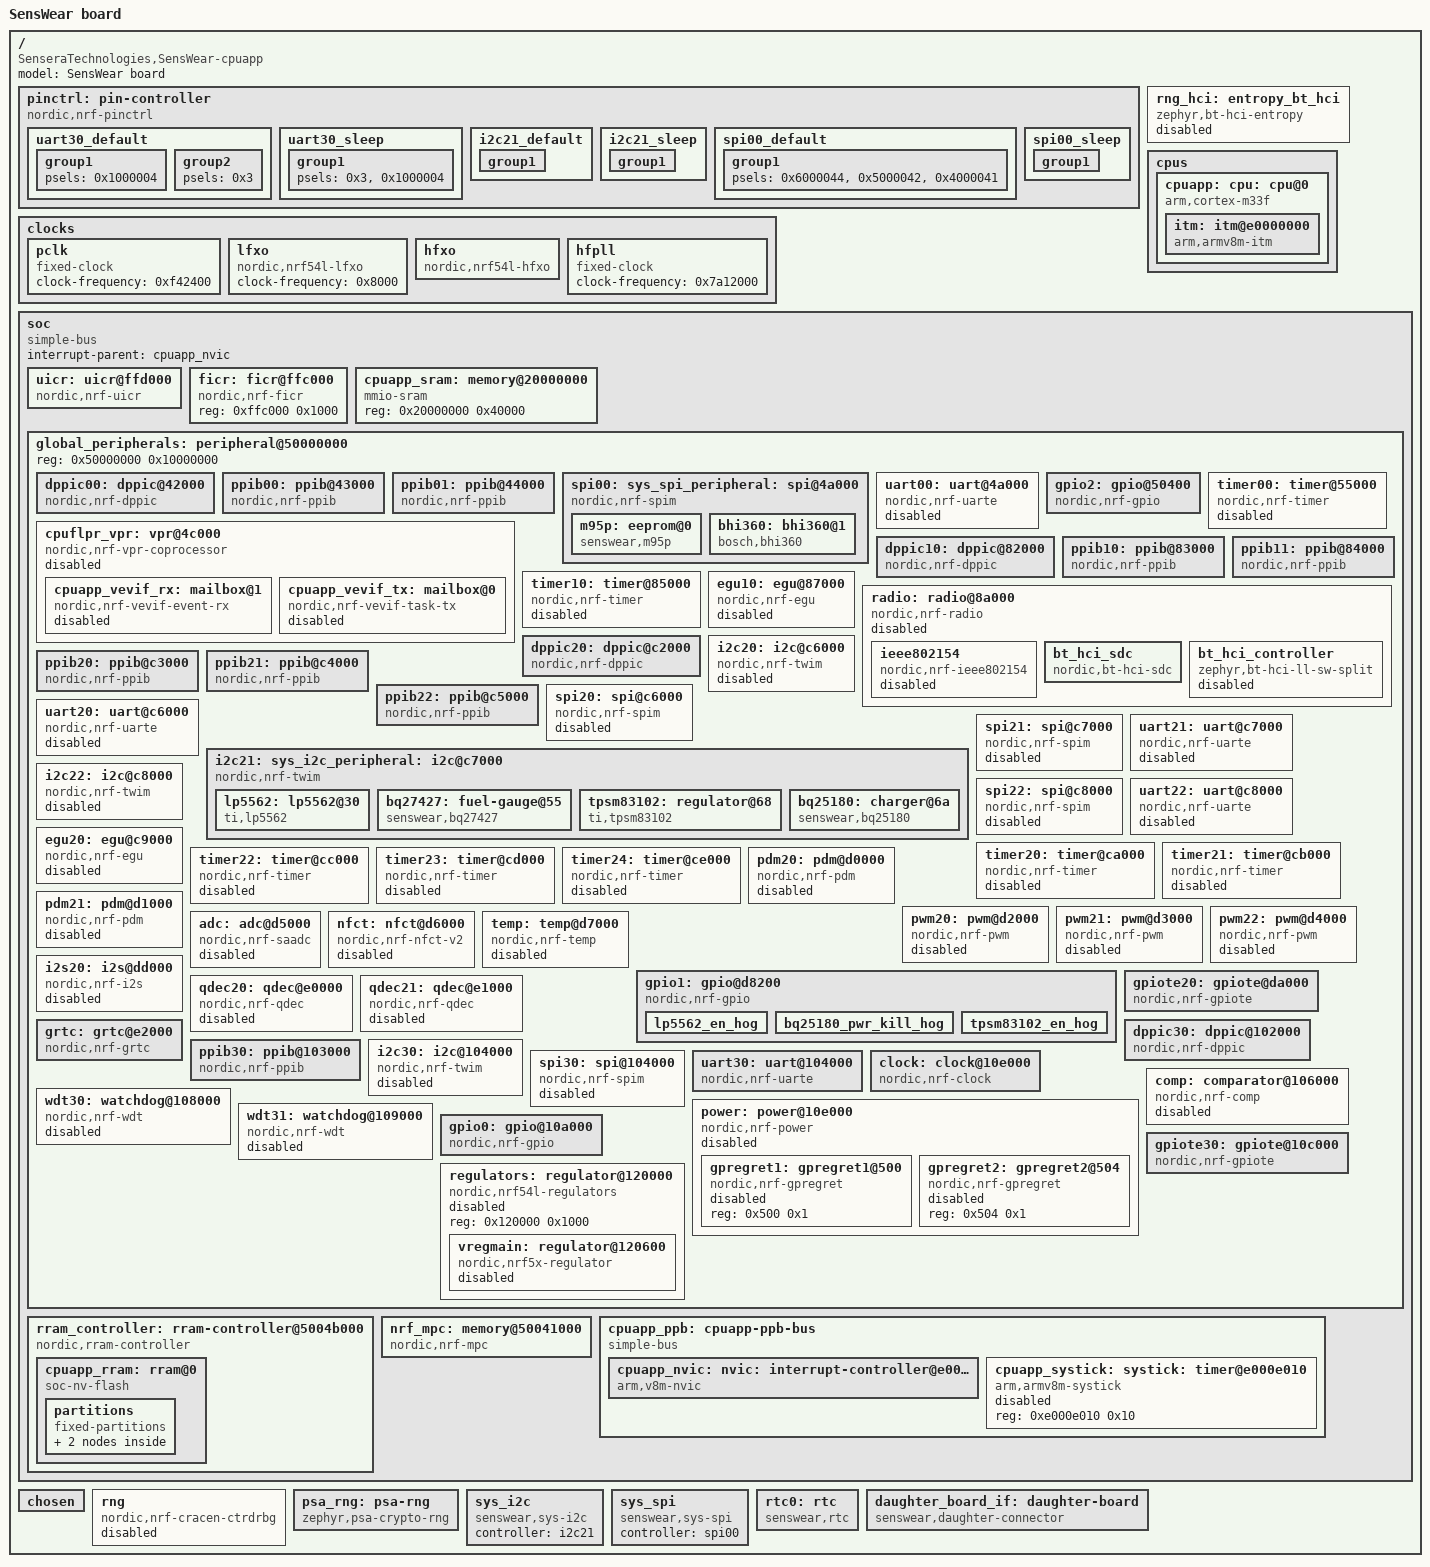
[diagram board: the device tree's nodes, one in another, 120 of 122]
/dts-v1/;

/* node '/' defined in zephyr\dts\vendor\nordic\nrf_common.dtsi:25 */
/ {
	#address-cells = < 0x1 >;                           /* in zephyr\dts\vendor\nordic\nrf54l_05_10_15.dtsi:19 */
	#size-cells = < 0x1 >;                              /* in zephyr\dts\vendor\nordic\nrf54l_05_10_15.dtsi:20 */
	model = "SensWear board";                           /* in ..\..\Users\salamid1\AppData\Local\Temp\senswear_fig4a_1164e335\boards\SenseraTechnologies\SensWear\SensWear_nrf54l15_cpuapp.dts:13 */
	compatible = "SenseraTechnologies,SensWear-cpuapp"; /* in ..\..\Users\salamid1\AppData\Local\Temp\senswear_fig4a_1164e335\boards\SenseraTechnologies\SensWear\SensWear_nrf54l15_cpuapp.dts:14 */

	/* node '/pin-controller' defined in zephyr\dts\vendor\nordic\nrf_common.dtsi:26 */
	pinctrl: pin-controller {
		compatible = "nordic,nrf-pinctrl"; /* in zephyr\dts\vendor\nordic\nrf_common.dtsi:31 */

		/* node '/pin-controller/uart30_default' defined in ..\..\Users\salamid1\AppData\Local\Temp\senswear_fig4a_1164e335\boards\SenseraTechnologies\SensWear\SensWear_nrf54l15_cpuapp.dts:121 */
		uart30_default: uart30_default {
			phandle = < 0xd >; /* in ..\..\Users\salamid1\AppData\Local\Temp\senswear_fig4a_1164e335\boards\SenseraTechnologies\SensWear\SensWear_nrf54l15_cpuapp.dts:85 */

			/* node '/pin-controller/uart30_default/group1' defined in ..\..\Users\salamid1\AppData\Local\Temp\senswear_fig4a_1164e335\boards\SenseraTechnologies\SensWear\SensWear_nrf54l15_cpuapp.dts:122 */
			group1 {
				psels = < 0x1000004 >; /* in ..\..\Users\salamid1\AppData\Local\Temp\senswear_fig4a_1164e335\boards\SenseraTechnologies\SensWear\SensWear_nrf54l15_cpuapp.dts:123 */
			};

			/* node '/pin-controller/uart30_default/group2' defined in ..\..\Users\salamid1\AppData\Local\Temp\senswear_fig4a_1164e335\boards\SenseraTechnologies\SensWear\SensWear_nrf54l15_cpuapp.dts:125 */
			group2 {
				psels = < 0x3 >; /* in ..\..\Users\salamid1\AppData\Local\Temp\senswear_fig4a_1164e335\boards\SenseraTechnologies\SensWear\SensWear_nrf54l15_cpuapp.dts:126 */
			};
		};

		/* node '/pin-controller/uart30_sleep' defined in ..\..\Users\salamid1\AppData\Local\Temp\senswear_fig4a_1164e335\boards\SenseraTechnologies\SensWear\SensWear_nrf54l15_cpuapp.dts:130 */
		uart30_sleep: uart30_sleep {
			phandle = < 0xe >; /* in ..\..\Users\salamid1\AppData\Local\Temp\senswear_fig4a_1164e335\boards\SenseraTechnologies\SensWear\SensWear_nrf54l15_cpuapp.dts:86 */

			/* node '/pin-controller/uart30_sleep/group1' defined in ..\..\Users\salamid1\AppData\Local\Temp\senswear_fig4a_1164e335\boards\SenseraTechnologies\SensWear\SensWear_nrf54l15_cpuapp.dts:131 */
			group1 {
				psels = < 0x3 >,
				        < 0x1000004 >; /* in ..\..\Users\salamid1\AppData\Local\Temp\senswear_fig4a_1164e335\boards\SenseraTechnologies\SensWear\SensWear_nrf54l15_cpuapp.dts:132 */
			};
		};

		/* node '/pin-controller/i2c21_default' defined in ..\..\Users\salamid1\AppData\Local\Temp\senswear_fig4a_1164e335\boards\SenseraTechnologies\SensWear\SensWear_nrf54l15_cpuapp.dts:137 */
		i2c21_default: i2c21_default {
			phandle = < 0x8 >; /* in ..\..\Users\salamid1\AppData\Local\Temp\senswear_fig4a_1164e335\boards\SenseraTechnologies\SensWear\SensWear_nrf54l15_cpuapp.dts:207 */

			/* node '/pin-controller/i2c21_default/group1' defined in ..\..\Users\salamid1\AppData\Local\Temp\senswear_fig4a_1164e335\boards\SenseraTechnologies\SensWear\SensWear_nrf54l15_cpuapp.dts:138 */
			group1 {
				psels = < 0xc000022 >,
				        < 0xb000023 >; /* in ..\..\Users\salamid1\AppData\Local\Temp\senswear_fig4a_1164e335\boards\SenseraTechnologies\SensWear\SensWear_nrf54l15_cpuapp.dts:139 */
				bias-pull-up;          /* in ..\..\Users\salamid1\AppData\Local\Temp\senswear_fig4a_1164e335\boards\SenseraTechnologies\SensWear\SensWear_nrf54l15_cpuapp.dts:141 */
			};
		};

		/* node '/pin-controller/i2c21_sleep' defined in ..\..\Users\salamid1\AppData\Local\Temp\senswear_fig4a_1164e335\boards\SenseraTechnologies\SensWear\SensWear_nrf54l15_cpuapp.dts:145 */
		i2c21_sleep: i2c21_sleep {
			phandle = < 0x9 >; /* in ..\..\Users\salamid1\AppData\Local\Temp\senswear_fig4a_1164e335\boards\SenseraTechnologies\SensWear\SensWear_nrf54l15_cpuapp.dts:208 */

			/* node '/pin-controller/i2c21_sleep/group1' defined in ..\..\Users\salamid1\AppData\Local\Temp\senswear_fig4a_1164e335\boards\SenseraTechnologies\SensWear\SensWear_nrf54l15_cpuapp.dts:146 */
			group1 {
				psels = < 0xc000022 >,
				        < 0xb000023 >; /* in ..\..\Users\salamid1\AppData\Local\Temp\senswear_fig4a_1164e335\boards\SenseraTechnologies\SensWear\SensWear_nrf54l15_cpuapp.dts:147 */
				low-power-enable;      /* in ..\..\Users\salamid1\AppData\Local\Temp\senswear_fig4a_1164e335\boards\SenseraTechnologies\SensWear\SensWear_nrf54l15_cpuapp.dts:149 */
			};
		};

		/* node '/pin-controller/spi00_default' defined in ..\..\Users\salamid1\AppData\Local\Temp\senswear_fig4a_1164e335\boards\SenseraTechnologies\SensWear\SensWear_nrf54l15_cpuapp.dts:153 */
		spi00_default: spi00_default {
			phandle = < 0x3 >; /* in ..\..\Users\salamid1\AppData\Local\Temp\senswear_fig4a_1164e335\boards\SenseraTechnologies\SensWear\SensWear_nrf54l15_cpuapp.dts:312 */

			/* node '/pin-controller/spi00_default/group1' defined in ..\..\Users\salamid1\AppData\Local\Temp\senswear_fig4a_1164e335\boards\SenseraTechnologies\SensWear\SensWear_nrf54l15_cpuapp.dts:154 */
			group1 {
				psels = < 0x6000044 >,
				        < 0x5000042 >,
				        < 0x4000041 >; /* in ..\..\Users\salamid1\AppData\Local\Temp\senswear_fig4a_1164e335\boards\SenseraTechnologies\SensWear\SensWear_nrf54l15_cpuapp.dts:155 */
			};
		};

		/* node '/pin-controller/spi00_sleep' defined in ..\..\Users\salamid1\AppData\Local\Temp\senswear_fig4a_1164e335\boards\SenseraTechnologies\SensWear\SensWear_nrf54l15_cpuapp.dts:161 */
		spi00_sleep: spi00_sleep {
			phandle = < 0x4 >; /* in ..\..\Users\salamid1\AppData\Local\Temp\senswear_fig4a_1164e335\boards\SenseraTechnologies\SensWear\SensWear_nrf54l15_cpuapp.dts:313 */

			/* node '/pin-controller/spi00_sleep/group1' defined in ..\..\Users\salamid1\AppData\Local\Temp\senswear_fig4a_1164e335\boards\SenseraTechnologies\SensWear\SensWear_nrf54l15_cpuapp.dts:162 */
			group1 {
				psels = < 0x6000044 >,
				        < 0x5000042 >,
				        < 0x4000041 >; /* in ..\..\Users\salamid1\AppData\Local\Temp\senswear_fig4a_1164e335\boards\SenseraTechnologies\SensWear\SensWear_nrf54l15_cpuapp.dts:163 */
				low-power-enable;      /* in ..\..\Users\salamid1\AppData\Local\Temp\senswear_fig4a_1164e335\boards\SenseraTechnologies\SensWear\SensWear_nrf54l15_cpuapp.dts:166 */
			};
		};
	};

	/* node '/entropy_bt_hci' defined in zephyr\dts\vendor\nordic\nrf_common.dtsi:34 */
	rng_hci: entropy_bt_hci {
		compatible = "zephyr,bt-hci-entropy"; /* in zephyr\dts\vendor\nordic\nrf_common.dtsi:35 */
		status = "disabled";                  /* in zephyr\dts\vendor\nordic\nrf_common.dtsi:36 */
	};

	/* node '/cpus' defined in zephyr\dts\vendor\nordic\nrf54l_05_10_15.dtsi:22 */
	cpus {
		#address-cells = < 0x1 >; /* in zephyr\dts\vendor\nordic\nrf54l_05_10_15.dtsi:23 */
		#size-cells = < 0x0 >;    /* in zephyr\dts\vendor\nordic\nrf54l_05_10_15.dtsi:24 */

		/* node '/cpus/cpu@0' defined in zephyr\dts\vendor\nordic\nrf54l_05_10_15.dtsi:26 */
		cpuapp: cpu: cpu@0 {
			compatible = "arm,cortex-m33f"; /* in zephyr\dts\vendor\nordic\nrf54l_05_10_15.dtsi:27 */
			reg = < 0x0 >;                  /* in zephyr\dts\vendor\nordic\nrf54l_05_10_15.dtsi:28 */
			device_type = "cpu";            /* in zephyr\dts\vendor\nordic\nrf54l_05_10_15.dtsi:29 */
			clocks = < &hfpll >;            /* in zephyr\dts\vendor\nordic\nrf54l_05_10_15.dtsi:30 */
			#address-cells = < 0x1 >;       /* in zephyr\dts\vendor\nordic\nrf54l_05_10_15.dtsi:31 */
			#size-cells = < 0x1 >;          /* in zephyr\dts\vendor\nordic\nrf54l_05_10_15.dtsi:32 */

			/* node '/cpus/cpu@0/itm@e0000000' defined in zephyr\dts\vendor\nordic\nrf54l_05_10_15.dtsi:34 */
			itm: itm@e0000000 {
				compatible = "arm,armv8m-itm";     /* in zephyr\dts\vendor\nordic\nrf54l_05_10_15.dtsi:35 */
				reg = < 0xe0000000 0x1000 >;       /* in zephyr\dts\vendor\nordic\nrf54l_05_10_15.dtsi:36 */
				swo-ref-frequency = < 0x7a12000 >; /* in zephyr\dts\vendor\nordic\nrf54l_05_10_15.dtsi:37 */
			};
		};
	};

	/* node '/clocks' defined in zephyr\dts\vendor\nordic\nrf54l_05_10_15.dtsi:52 */
	clocks {

		/* node '/clocks/pclk' defined in zephyr\dts\vendor\nordic\nrf54l_05_10_15.dtsi:53 */
		pclk: pclk {
			compatible = "fixed-clock";     /* in zephyr\dts\vendor\nordic\nrf54l_05_10_15.dtsi:54 */
			#clock-cells = < 0x0 >;         /* in zephyr\dts\vendor\nordic\nrf54l_05_10_15.dtsi:55 */
			clock-frequency = < 0xf42400 >; /* in zephyr\dts\vendor\nordic\nrf54l_05_10_15.dtsi:56 */
			phandle = < 0xc >;              /* in zephyr\dts\vendor\nordic\nrf54l_05_10_15.dtsi:596 */
		};

		/* node '/clocks/lfxo' defined in zephyr\dts\vendor\nordic\nrf54l_05_10_15.dtsi:59 */
		lfxo: lfxo {
			compatible = "nordic,nrf54l-lfxo"; /* in zephyr\dts\vendor\nordic\nrf54l_05_10_15.dtsi:60 */
			#clock-cells = < 0x0 >;            /* in zephyr\dts\vendor\nordic\nrf54l_05_10_15.dtsi:61 */
			clock-frequency = < 0x8000 >;      /* in zephyr\dts\vendor\nordic\nrf54l_05_10_15.dtsi:62 */
			phandle = < 0xb >;                 /* in zephyr\dts\vendor\nordic\nrf54l_05_10_15.dtsi:596 */
		};

		/* node '/clocks/hfxo' defined in zephyr\dts\vendor\nordic\nrf54l_05_10_15.dtsi:65 */
		hfxo: hfxo {
			compatible = "nordic,nrf54l-hfxo"; /* in zephyr\dts\vendor\nordic\nrf54l_05_10_15.dtsi:66 */
			#clock-cells = < 0x0 >;            /* in zephyr\dts\vendor\nordic\nrf54l_05_10_15.dtsi:67 */
			clock-frequency = < 0x1e84800 >;   /* in zephyr\dts\vendor\nordic\nrf54l_05_10_15.dtsi:68 */
			startup-time-us = < 0x672 >;       /* in zephyr\dts\vendor\nordic\nrf54l_05_10_15.dtsi:69 */
			phandle = < 0x7 >;                 /* in zephyr\dts\vendor\nordic\nrf54l_05_10_15.dtsi:243 */
		};

		/* node '/clocks/hfpll' defined in zephyr\dts\vendor\nordic\nrf54l_05_10_15.dtsi:72 */
		hfpll: hfpll {
			compatible = "fixed-clock";      /* in zephyr\dts\vendor\nordic\nrf54l_05_10_15.dtsi:73 */
			#clock-cells = < 0x0 >;          /* in zephyr\dts\vendor\nordic\nrf54l_05_10_15.dtsi:74 */
			clock-frequency = < 0x7a12000 >; /* in zephyr\dts\vendor\nordic\nrf54l_05_10_15.dtsi:75 */
			phandle = < 0x1 >;               /* in zephyr\dts\vendor\nordic\nrf54l_05_10_15.dtsi:30 */
		};
	};

	/* node '/soc' defined in zephyr\dts\vendor\nordic\nrf54l_05_10_15.dtsi:79 */
	soc {
		#address-cells = < 0x1 >;            /* in zephyr\dts\vendor\nordic\nrf54l_05_10_15.dtsi:80 */
		#size-cells = < 0x1 >;               /* in zephyr\dts\vendor\nordic\nrf54l_05_10_15.dtsi:81 */
		compatible = "simple-bus";           /* in zephyr\dts\arm\nordic\nrf54l_05_10_15_cpuapp.dtsi:23 */
		interrupt-parent = < &cpuapp_nvic >; /* in zephyr\dts\arm\nordic\nrf54l_05_10_15_cpuapp.dtsi:24 */
		ranges;                              /* in zephyr\dts\arm\nordic\nrf54l_05_10_15_cpuapp.dtsi:25 */

		/* node '/soc/uicr@ffd000' defined in zephyr\dts\vendor\nordic\nrf54l_05_10_15.dtsi:86 */
		uicr: uicr@ffd000 {
			compatible = "nordic,nrf-uicr";   /* in zephyr\dts\vendor\nordic\nrf54l_05_10_15.dtsi:87 */
			reg = < 0xffd000 0x1000 >;        /* in zephyr\dts\vendor\nordic\nrf54l_05_10_15.dtsi:88 */
			ranges = < 0x0 0xffd000 0x1000 >; /* in zephyr\dts\vendor\nordic\nrf54l_05_10_15.dtsi:89 */
			#address-cells = < 0x1 >;         /* in zephyr\dts\vendor\nordic\nrf54l_05_10_15.dtsi:90 */
			#size-cells = < 0x1 >;            /* in zephyr\dts\vendor\nordic\nrf54l_05_10_15.dtsi:91 */
			nfct-pins-as-gpios;               /* in ..\..\Users\salamid1\AppData\Local\Temp\senswear_fig4a_1164e335\boards\SenseraTechnologies\SensWear\SensWear_nrf54l15_cpuapp.dts:307 */
		};

		/* node '/soc/ficr@ffc000' defined in zephyr\dts\vendor\nordic\nrf54l_05_10_15.dtsi:95 */
		ficr: ficr@ffc000 {
			compatible = "nordic,nrf-ficr"; /* in zephyr\dts\vendor\nordic\nrf54l_05_10_15.dtsi:96 */
			reg = < 0xffc000 0x1000 >;      /* in zephyr\dts\vendor\nordic\nrf54l_05_10_15.dtsi:97 */
			#nordic,ficr-cells = < 0x1 >;   /* in zephyr\dts\vendor\nordic\nrf54l_05_10_15.dtsi:98 */
		};

		/* node '/soc/memory@20000000' defined in zephyr\dts\vendor\nordic\nrf54l_05_10_15.dtsi:101 */
		cpuapp_sram: memory@20000000 {
			compatible = "mmio-sram";            /* in zephyr\dts\vendor\nordic\nrf54l_05_10_15.dtsi:102 */
			#address-cells = < 0x1 >;            /* in zephyr\dts\vendor\nordic\nrf54l_05_10_15.dtsi:103 */
			#size-cells = < 0x1 >;               /* in zephyr\dts\vendor\nordic\nrf54l_05_10_15.dtsi:104 */
			reg = < 0x20000000 0x40000 >;        /* in zephyr\dts\vendor\nordic\nrf54l15.dtsi:10 */
			ranges = < 0x0 0x20000000 0x40000 >; /* in zephyr\dts\vendor\nordic\nrf54l15.dtsi:11 */
			status = "okay";                     /* in ..\..\Users\salamid1\AppData\Local\Temp\senswear_fig4a_1164e335\boards\SenseraTechnologies\SensWear\SensWear_nrf54l15_cpuapp.dts:100 */
		};

		/* node '/soc/peripheral@50000000' defined in zephyr\dts\vendor\nordic\nrf54l_05_10_15.dtsi:114 */
		global_peripherals: peripheral@50000000 {
			reg = < 0x50000000 0x10000000 >;        /* in zephyr\dts\vendor\nordic\nrf54l_05_10_15.dtsi:115 */
			#address-cells = < 0x1 >;               /* in zephyr\dts\vendor\nordic\nrf54l_05_10_15.dtsi:116 */
			#size-cells = < 0x1 >;                  /* in zephyr\dts\vendor\nordic\nrf54l_05_10_15.dtsi:117 */
			ranges = < 0x0 0x50000000 0x10000000 >; /* in zephyr\dts\vendor\nordic\nrf54l_05_10_15.dtsi:118 */

			/* node '/soc/peripheral@50000000/dppic@42000' defined in zephyr\dts\vendor\nordic\nrf54l_05_10_15.dtsi:121 */
			dppic00: dppic@42000 {
				compatible = "nordic,nrf-dppic"; /* in zephyr\dts\vendor\nordic\nrf54l_05_10_15.dtsi:122 */
				reg = < 0x42000 0x808 >;         /* in zephyr\dts\vendor\nordic\nrf54l_05_10_15.dtsi:123 */
				channels = < 0x8 >;              /* in zephyr\dts\vendor\nordic\nrf54l_05_10_15.dtsi:125 */
				groups = < 0x2 >;                /* in zephyr\dts\vendor\nordic\nrf54l_05_10_15.dtsi:126 */
				status = "okay";                 /* in zephyr\dts\arm\nordic\nrf54l_05_10_15_cpuapp.dtsi:95 */
			};

			/* node '/soc/peripheral@50000000/ppib@43000' defined in zephyr\dts\vendor\nordic\nrf54l_05_10_15.dtsi:129 */
			ppib00: ppib@43000 {
				compatible = "nordic,nrf-ppib"; /* in zephyr\dts\vendor\nordic\nrf54l_05_10_15.dtsi:130 */
				reg = < 0x43000 0x1000 >;       /* in zephyr\dts\vendor\nordic\nrf54l_05_10_15.dtsi:131 */
				channels = < 0x8 >;             /* in zephyr\dts\vendor\nordic\nrf54l_05_10_15.dtsi:133 */
				status = "okay";                /* in zephyr\dts\arm\nordic\nrf54l_05_10_15_cpuapp.dtsi:111 */
			};

			/* node '/soc/peripheral@50000000/ppib@44000' defined in zephyr\dts\vendor\nordic\nrf54l_05_10_15.dtsi:136 */
			ppib01: ppib@44000 {
				compatible = "nordic,nrf-ppib"; /* in zephyr\dts\vendor\nordic\nrf54l_05_10_15.dtsi:137 */
				reg = < 0x44000 0x1000 >;       /* in zephyr\dts\vendor\nordic\nrf54l_05_10_15.dtsi:138 */
				channels = < 0x8 >;             /* in zephyr\dts\vendor\nordic\nrf54l_05_10_15.dtsi:140 */
				status = "okay";                /* in zephyr\dts\arm\nordic\nrf54l_05_10_15_cpuapp.dtsi:115 */
			};

			/* node '/soc/peripheral@50000000/spi@4a000' defined in zephyr\dts\vendor\nordic\nrf54l_05_10_15.dtsi:143 */
			spi00: sys_spi_peripheral: spi@4a000 {
				compatible = "nordic,nrf-spim"; /* in zephyr\dts\vendor\nordic\nrf54l_05_10_15.dtsi:150 */
				#address-cells = < 0x1 >;       /* in zephyr\dts\vendor\nordic\nrf54l_05_10_15.dtsi:151 */
				#size-cells = < 0x0 >;          /* in zephyr\dts\vendor\nordic\nrf54l_05_10_15.dtsi:152 */
				reg = < 0x4a000 0x1000 >;       /* in zephyr\dts\vendor\nordic\nrf54l_05_10_15.dtsi:153 */
				interrupts = < 0x4a 0x1 >;      /* in zephyr\dts\vendor\nordic\nrf54l_05_10_15.dtsi:154 */
				clocks = < &hfpll >;            /* in zephyr\dts\vendor\nordic\nrf54l_05_10_15.dtsi:155 */
				max-frequency = < 0x1e84800 >;  /* in zephyr\dts\vendor\nordic\nrf54l_05_10_15.dtsi:156 */
				easydma-maxcnt-bits = < 0x10 >; /* in zephyr\dts\vendor\nordic\nrf54l_05_10_15.dtsi:157 */
				rx-delay-supported;             /* in zephyr\dts\vendor\nordic\nrf54l_05_10_15.dtsi:158 */
				rx-delay = < 0x1 >;             /* in zephyr\dts\vendor\nordic\nrf54l_05_10_15.dtsi:159 */
				status = "okay";                /* in ..\..\Users\salamid1\AppData\Local\Temp\senswear_fig4a_1164e335\boards\SenseraTechnologies\SensWear\SensWear_nrf54l15_cpuapp.dts:311 */
				pinctrl-0 = < &spi00_default >; /* in ..\..\Users\salamid1\AppData\Local\Temp\senswear_fig4a_1164e335\boards\SenseraTechnologies\SensWear\SensWear_nrf54l15_cpuapp.dts:312 */
				pinctrl-1 = < &spi00_sleep >;   /* in ..\..\Users\salamid1\AppData\Local\Temp\senswear_fig4a_1164e335\boards\SenseraTechnologies\SensWear\SensWear_nrf54l15_cpuapp.dts:313 */
				pinctrl-names = "default",
				                "sleep";        /* in ..\..\Users\salamid1\AppData\Local\Temp\senswear_fig4a_1164e335\boards\SenseraTechnologies\SensWear\SensWear_nrf54l15_cpuapp.dts:314 */
				phandle = < 0x11 >;             /* in ..\..\Users\salamid1\AppData\Local\Temp\senswear_fig4a_1164e335\boards\SenseraTechnologies\SensWear\SensWear_nrf54l15_cpuapp.dts:38 */

				/* node '/soc/peripheral@50000000/spi@4a000/eeprom@0' defined in ..\..\Users\salamid1\AppData\Local\Temp\senswear_fig4a_1164e335\boards\SenseraTechnologies\SensWear\SensWear_nrf54l15_cpuapp.dts:324 */
				m95p: eeprom@0 {
					compatible = "senswear,m95p";     /* in ..\..\Users\salamid1\AppData\Local\Temp\senswear_fig4a_1164e335\boards\SenseraTechnologies\SensWear\SensWear_nrf54l15_cpuapp.dts:325 */
					reg = < 0x0 >;                    /* in ..\..\Users\salamid1\AppData\Local\Temp\senswear_fig4a_1164e335\boards\SenseraTechnologies\SensWear\SensWear_nrf54l15_cpuapp.dts:326 */
					spi-max-frequency = < 0x7a1200 >; /* in ..\..\Users\salamid1\AppData\Local\Temp\senswear_fig4a_1164e335\boards\SenseraTechnologies\SensWear\SensWear_nrf54l15_cpuapp.dts:327 */
					cs-gpios = < &gpio2 0x3 0x1 >;    /* in ..\..\Users\salamid1\AppData\Local\Temp\senswear_fig4a_1164e335\boards\SenseraTechnologies\SensWear\SensWear_nrf54l15_cpuapp.dts:328 */
					size = < 0x400000 >;              /* in ..\..\Users\salamid1\AppData\Local\Temp\senswear_fig4a_1164e335\boards\SenseraTechnologies\SensWear\SensWear_nrf54l15_cpuapp.dts:329 */
					address-width = < 0x18 >;         /* in ..\..\Users\salamid1\AppData\Local\Temp\senswear_fig4a_1164e335\boards\SenseraTechnologies\SensWear\SensWear_nrf54l15_cpuapp.dts:330 */
					pagesize = < 0x200 >;             /* in ..\..\Users\salamid1\AppData\Local\Temp\senswear_fig4a_1164e335\boards\SenseraTechnologies\SensWear\SensWear_nrf54l15_cpuapp.dts:331 */
					timeout = < 0x64 >;               /* in ..\..\Users\salamid1\AppData\Local\Temp\senswear_fig4a_1164e335\boards\SenseraTechnologies\SensWear\SensWear_nrf54l15_cpuapp.dts:332 */
					status = "okay";                  /* in ..\..\Users\salamid1\AppData\Local\Temp\senswear_fig4a_1164e335\boards\SenseraTechnologies\SensWear\SensWear_nrf54l15_cpuapp.dts:333 */
				};

				/* node '/soc/peripheral@50000000/spi@4a000/bhi360@1' defined in ..\..\Users\salamid1\AppData\Local\Temp\senswear_fig4a_1164e335\boards\SenseraTechnologies\SensWear\SensWear_nrf54l15_cpuapp.dts:339 */
				bhi360: bhi360@1 {
					compatible = "bosch,bhi360";      /* in ..\..\Users\salamid1\AppData\Local\Temp\senswear_fig4a_1164e335\boards\SenseraTechnologies\SensWear\SensWear_nrf54l15_cpuapp.dts:340 */
					reg = < 0x1 >;                    /* in ..\..\Users\salamid1\AppData\Local\Temp\senswear_fig4a_1164e335\boards\SenseraTechnologies\SensWear\SensWear_nrf54l15_cpuapp.dts:341 */
					spi-max-frequency = < 0x7a1200 >; /* in ..\..\Users\salamid1\AppData\Local\Temp\senswear_fig4a_1164e335\boards\SenseraTechnologies\SensWear\SensWear_nrf54l15_cpuapp.dts:342 */
					cs-gpios = < &gpio2 0x5 0x1 >;    /* in ..\..\Users\salamid1\AppData\Local\Temp\senswear_fig4a_1164e335\boards\SenseraTechnologies\SensWear\SensWear_nrf54l15_cpuapp.dts:343 */
					int-gpios = < &gpio1 0x9 0x1 >;   /* in ..\..\Users\salamid1\AppData\Local\Temp\senswear_fig4a_1164e335\boards\SenseraTechnologies\SensWear\SensWear_nrf54l15_cpuapp.dts:344 */
					reset-gpios = < &gpio2 0x7 0x1 >; /* in ..\..\Users\salamid1\AppData\Local\Temp\senswear_fig4a_1164e335\boards\SenseraTechnologies\SensWear\SensWear_nrf54l15_cpuapp.dts:345 */
					gpio0-gpios = < &gpio1 0xa 0x0 >; /* in ..\..\Users\salamid1\AppData\Local\Temp\senswear_fig4a_1164e335\boards\SenseraTechnologies\SensWear\SensWear_nrf54l15_cpuapp.dts:346 */
					gpio1-gpios = < &gpio2 0x6 0x0 >; /* in ..\..\Users\salamid1\AppData\Local\Temp\senswear_fig4a_1164e335\boards\SenseraTechnologies\SensWear\SensWear_nrf54l15_cpuapp.dts:347 */
					status = "okay";                  /* in ..\..\Users\salamid1\AppData\Local\Temp\senswear_fig4a_1164e335\boards\SenseraTechnologies\SensWear\SensWear_nrf54l15_cpuapp.dts:348 */
				};
			};

			/* node '/soc/peripheral@50000000/uart@4a000' defined in zephyr\dts\vendor\nordic\nrf54l_05_10_15.dtsi:163 */
			uart00: uart@4a000 {
				compatible = "nordic,nrf-uarte"; /* in zephyr\dts\vendor\nordic\nrf54l_05_10_15.dtsi:164 */
				reg = < 0x4a000 0x1000 >;        /* in zephyr\dts\vendor\nordic\nrf54l_05_10_15.dtsi:165 */
				interrupts = < 0x4a 0x1 >;       /* in zephyr\dts\vendor\nordic\nrf54l_05_10_15.dtsi:166 */
				clocks = < &hfpll >;             /* in zephyr\dts\vendor\nordic\nrf54l_05_10_15.dtsi:167 */
				status = "disabled";             /* in zephyr\dts\vendor\nordic\nrf54l_05_10_15.dtsi:168 */
				endtx-stoptx-supported;          /* in zephyr\dts\vendor\nordic\nrf54l_05_10_15.dtsi:169 */
				frame-timeout-supported;         /* in zephyr\dts\vendor\nordic\nrf54l_05_10_15.dtsi:170 */
			};

			/* node '/soc/peripheral@50000000/vpr@4c000' defined in zephyr\dts\vendor\nordic\nrf54l_05_10_15.dtsi:173 */
			cpuflpr_vpr: vpr@4c000 {
				compatible = "nordic,nrf-vpr-coprocessor"; /* in zephyr\dts\vendor\nordic\nrf54l_05_10_15.dtsi:174 */
				reg = < 0x4c000 0x1000 >;                  /* in zephyr\dts\vendor\nordic\nrf54l_05_10_15.dtsi:175 */
				ranges = < 0x0 0x4c000 0x1000 >;           /* in zephyr\dts\vendor\nordic\nrf54l_05_10_15.dtsi:176 */
				#address-cells = < 0x1 >;                  /* in zephyr\dts\vendor\nordic\nrf54l_05_10_15.dtsi:177 */
				#size-cells = < 0x1 >;                     /* in zephyr\dts\vendor\nordic\nrf54l_05_10_15.dtsi:178 */
				status = "disabled";                       /* in zephyr\dts\vendor\nordic\nrf54l_05_10_15.dtsi:179 */
				enable-secure;                             /* in zephyr\dts\vendor\nordic\nrf54l_05_10_15.dtsi:180 */
				hibernation-ram-block = < 0x20 >;          /* in zephyr\dts\vendor\nordic\nrf54l_05_10_15.dtsi:181 */

				/* node '/soc/peripheral@50000000/vpr@4c000/mailbox@1' defined in zephyr\dts\arm\nordic\nrf54l_05_10_15_cpuapp.dtsi:44 */
				cpuapp_vevif_rx: mailbox@1 {
					compatible = "nordic,nrf-vevif-event-rx"; /* in zephyr\dts\arm\nordic\nrf54l_05_10_15_cpuapp.dtsi:45 */
					reg = < 0x1 0x1000 >;                     /* in zephyr\dts\arm\nordic\nrf54l_05_10_15_cpuapp.dtsi:46 */
					status = "disabled";                      /* in zephyr\dts\arm\nordic\nrf54l_05_10_15_cpuapp.dtsi:47 */
					interrupts = < 0x4c 0x1 >;                /* in zephyr\dts\arm\nordic\nrf54l_05_10_15_cpuapp.dtsi:48 */
					#mbox-cells = < 0x1 >;                    /* in zephyr\dts\arm\nordic\nrf54l_05_10_15_cpuapp.dtsi:49 */
					nordic,events = < 0x1 >;                  /* in zephyr\dts\arm\nordic\nrf54l_05_10_15_cpuapp.dtsi:50 */
					nordic,events-mask = < 0x100000 >;        /* in zephyr\dts\arm\nordic\nrf54l_05_10_15_cpuapp.dtsi:51 */
				};

				/* node '/soc/peripheral@50000000/vpr@4c000/mailbox@0' defined in zephyr\dts\arm\nordic\nrf54l_05_10_15_cpuapp.dtsi:54 */
				cpuapp_vevif_tx: mailbox@0 {
					compatible = "nordic,nrf-vevif-task-tx"; /* in zephyr\dts\arm\nordic\nrf54l_05_10_15_cpuapp.dtsi:55 */
					reg = < 0x0 0x1000 >;                    /* in zephyr\dts\arm\nordic\nrf54l_05_10_15_cpuapp.dtsi:56 */
					#mbox-cells = < 0x1 >;                   /* in zephyr\dts\arm\nordic\nrf54l_05_10_15_cpuapp.dtsi:57 */
					nordic,tasks = < 0x7 >;                  /* in zephyr\dts\arm\nordic\nrf54l_05_10_15_cpuapp.dtsi:58 */
					nordic,tasks-mask = < 0x7f0000 >;        /* in zephyr\dts\arm\nordic\nrf54l_05_10_15_cpuapp.dtsi:59 */
					status = "disabled";                     /* in zephyr\dts\arm\nordic\nrf54l_05_10_15_cpuapp.dtsi:60 */
				};
			};

			/* node '/soc/peripheral@50000000/gpio@50400' defined in zephyr\dts\vendor\nordic\nrf54l_05_10_15.dtsi:193 */
			gpio2: gpio@50400 {
				compatible = "nordic,nrf-gpio"; /* in zephyr\dts\vendor\nordic\nrf54l_05_10_15.dtsi:194 */
				gpio-controller;                /* in zephyr\dts\vendor\nordic\nrf54l_05_10_15.dtsi:195 */
				reg = < 0x50400 0x300 >;        /* in zephyr\dts\vendor\nordic\nrf54l_05_10_15.dtsi:196 */
				#gpio-cells = < 0x2 >;          /* in zephyr\dts\vendor\nordic\nrf54l_05_10_15.dtsi:197 */
				ngpios = < 0xb >;               /* in zephyr\dts\vendor\nordic\nrf54l_05_10_15.dtsi:198 */
				port = < 0x2 >;                 /* in zephyr\dts\vendor\nordic\nrf54l_05_10_15.dtsi:200 */
				status = "okay";                /* in ..\..\Users\salamid1\AppData\Local\Temp\senswear_fig4a_1164e335\boards\SenseraTechnologies\SensWear\SensWear_nrf54l15_cpuapp.dts:303 */
				phandle = < 0x5 >;              /* in ..\..\Users\salamid1\AppData\Local\Temp\senswear_fig4a_1164e335\boards\SenseraTechnologies\SensWear\SensWear_nrf54l15_cpuapp.dts:328 */
			};

			/* node '/soc/peripheral@50000000/timer@55000' defined in zephyr\dts\vendor\nordic\nrf54l_05_10_15.dtsi:203 */
			timer00: timer@55000 {
				compatible = "nordic,nrf-timer"; /* in zephyr\dts\vendor\nordic\nrf54l_05_10_15.dtsi:204 */
				status = "disabled";             /* in zephyr\dts\vendor\nordic\nrf54l_05_10_15.dtsi:205 */
				reg = < 0x55000 0x1000 >;        /* in zephyr\dts\vendor\nordic\nrf54l_05_10_15.dtsi:206 */
				cc-num = < 0x6 >;                /* in zephyr\dts\vendor\nordic\nrf54l_05_10_15.dtsi:207 */
				max-bit-width = < 0x20 >;        /* in zephyr\dts\vendor\nordic\nrf54l_05_10_15.dtsi:208 */
				interrupts = < 0x55 0x1 >;       /* in zephyr\dts\vendor\nordic\nrf54l_05_10_15.dtsi:209 */
				clocks = < &hfpll >;             /* in zephyr\dts\vendor\nordic\nrf54l_05_10_15.dtsi:210 */
				prescaler = < 0x0 >;             /* in zephyr\dts\vendor\nordic\nrf54l_05_10_15.dtsi:211 */
			};

			/* node '/soc/peripheral@50000000/dppic@82000' defined in zephyr\dts\vendor\nordic\nrf54l_05_10_15.dtsi:214 */
			dppic10: dppic@82000 {
				compatible = "nordic,nrf-dppic"; /* in zephyr\dts\vendor\nordic\nrf54l_05_10_15.dtsi:215 */
				reg = < 0x82000 0x808 >;         /* in zephyr\dts\vendor\nordic\nrf54l_05_10_15.dtsi:216 */
				channels = < 0x18 >;             /* in zephyr\dts\vendor\nordic\nrf54l_05_10_15.dtsi:218 */
				groups = < 0x6 >;                /* in zephyr\dts\vendor\nordic\nrf54l_05_10_15.dtsi:219 */
				status = "okay";                 /* in zephyr\dts\arm\nordic\nrf54l_05_10_15_cpuapp.dtsi:99 */
			};

			/* node '/soc/peripheral@50000000/ppib@83000' defined in zephyr\dts\vendor\nordic\nrf54l_05_10_15.dtsi:222 */
			ppib10: ppib@83000 {
				compatible = "nordic,nrf-ppib"; /* in zephyr\dts\vendor\nordic\nrf54l_05_10_15.dtsi:223 */
				reg = < 0x83000 0x1000 >;       /* in zephyr\dts\vendor\nordic\nrf54l_05_10_15.dtsi:224 */
				channels = < 0x8 >;             /* in zephyr\dts\vendor\nordic\nrf54l_05_10_15.dtsi:226 */
				status = "okay";                /* in zephyr\dts\arm\nordic\nrf54l_05_10_15_cpuapp.dtsi:119 */
			};

			/* node '/soc/peripheral@50000000/ppib@84000' defined in zephyr\dts\vendor\nordic\nrf54l_05_10_15.dtsi:229 */
			ppib11: ppib@84000 {
				compatible = "nordic,nrf-ppib"; /* in zephyr\dts\vendor\nordic\nrf54l_05_10_15.dtsi:230 */
				reg = < 0x84000 0x1000 >;       /* in zephyr\dts\vendor\nordic\nrf54l_05_10_15.dtsi:231 */
				channels = < 0x10 >;            /* in zephyr\dts\vendor\nordic\nrf54l_05_10_15.dtsi:233 */
				status = "okay";                /* in zephyr\dts\arm\nordic\nrf54l_05_10_15_cpuapp.dtsi:123 */
			};

			/* node '/soc/peripheral@50000000/timer@85000' defined in zephyr\dts\vendor\nordic\nrf54l_05_10_15.dtsi:236 */
			timer10: timer@85000 {
				compatible = "nordic,nrf-timer"; /* in zephyr\dts\vendor\nordic\nrf54l_05_10_15.dtsi:237 */
				status = "disabled";             /* in zephyr\dts\vendor\nordic\nrf54l_05_10_15.dtsi:238 */
				reg = < 0x85000 0x1000 >;        /* in zephyr\dts\vendor\nordic\nrf54l_05_10_15.dtsi:239 */
				cc-num = < 0x8 >;                /* in zephyr\dts\vendor\nordic\nrf54l_05_10_15.dtsi:240 */
				max-bit-width = < 0x20 >;        /* in zephyr\dts\vendor\nordic\nrf54l_05_10_15.dtsi:241 */
				interrupts = < 0x85 0x1 >;       /* in zephyr\dts\vendor\nordic\nrf54l_05_10_15.dtsi:242 */
				clocks = < &hfxo >;              /* in zephyr\dts\vendor\nordic\nrf54l_05_10_15.dtsi:243 */
				prescaler = < 0x0 >;             /* in zephyr\dts\vendor\nordic\nrf54l_05_10_15.dtsi:244 */
			};

			/* node '/soc/peripheral@50000000/egu@87000' defined in zephyr\dts\vendor\nordic\nrf54l_05_10_15.dtsi:247 */
			egu10: egu@87000 {
				compatible = "nordic,nrf-egu"; /* in zephyr\dts\vendor\nordic\nrf54l_05_10_15.dtsi:248 */
				reg = < 0x87000 0x1000 >;      /* in zephyr\dts\vendor\nordic\nrf54l_05_10_15.dtsi:249 */
				interrupts = < 0x87 0x1 >;     /* in zephyr\dts\vendor\nordic\nrf54l_05_10_15.dtsi:250 */
				status = "disabled";           /* in zephyr\dts\vendor\nordic\nrf54l_05_10_15.dtsi:251 */
			};

			/* node '/soc/peripheral@50000000/radio@8a000' defined in zephyr\dts\vendor\nordic\nrf54l_05_10_15.dtsi:254 */
			radio: radio@8a000 {
				compatible = "nordic,nrf-radio"; /* in zephyr\dts\vendor\nordic\nrf54l_05_10_15.dtsi:255 */
				reg = < 0x8a000 0x1000 >;        /* in zephyr\dts\vendor\nordic\nrf54l_05_10_15.dtsi:256 */
				interrupts = < 0x8a 0x1 >;       /* in zephyr\dts\vendor\nordic\nrf54l_05_10_15.dtsi:257 */
				status = "disabled";             /* in zephyr\dts\vendor\nordic\nrf54l_05_10_15.dtsi:258 */
				dfe-supported;                   /* in zephyr\dts\vendor\nordic\nrf54l_05_10_15.dtsi:259 */
				ieee802154-supported;            /* in zephyr\dts\vendor\nordic\nrf54l_05_10_15.dtsi:260 */
				ble-2mbps-supported;             /* in zephyr\dts\vendor\nordic\nrf54l_05_10_15.dtsi:261 */
				ble-coded-phy-supported;         /* in zephyr\dts\vendor\nordic\nrf54l_05_10_15.dtsi:262 */
				ble-cs-supported;                /* in zephyr\dts\vendor\nordic\nrf54l_05_10_15.dtsi:263 */

				/* node '/soc/peripheral@50000000/radio@8a000/ieee802154' defined in zephyr\dts\vendor\nordic\nrf54l_05_10_15.dtsi:265 */
				ieee802154: ieee802154 {
					compatible = "nordic,nrf-ieee802154"; /* in zephyr\dts\vendor\nordic\nrf54l_05_10_15.dtsi:266 */
					status = "disabled";                  /* in zephyr\dts\vendor\nordic\nrf54l_05_10_15.dtsi:267 */
				};

				/* node '/soc/peripheral@50000000/radio@8a000/bt_hci_sdc' defined in zephyr\dts\vendor\nordic\nrf54l_05_10_15.dtsi:270 */
				bt_hci_sdc: bt_hci_sdc {
					compatible = "nordic,bt-hci-sdc"; /* in zephyr\dts\vendor\nordic\nrf54l_05_10_15.dtsi:271 */
					status = "okay";                  /* in zephyr\dts\arm\nordic\nrf54l_05_10_15_cpuapp.dtsi:40 */
				};

				/* node '/soc/peripheral@50000000/radio@8a000/bt_hci_controller' defined in zephyr\dts\vendor\nordic\nrf54l_05_10_15.dtsi:275 */
				bt_hci_controller: bt_hci_controller {
					compatible = "zephyr,bt-hci-ll-sw-split"; /* in zephyr\dts\vendor\nordic\nrf54l_05_10_15.dtsi:276 */
					status = "disabled";                      /* in zephyr\dts\vendor\nordic\nrf54l_05_10_15.dtsi:277 */
				};
			};

			/* node '/soc/peripheral@50000000/dppic@c2000' defined in zephyr\dts\vendor\nordic\nrf54l_05_10_15.dtsi:281 */
			dppic20: dppic@c2000 {
				compatible = "nordic,nrf-dppic"; /* in zephyr\dts\vendor\nordic\nrf54l_05_10_15.dtsi:282 */
				reg = < 0xc2000 0x808 >;         /* in zephyr\dts\vendor\nordic\nrf54l_05_10_15.dtsi:283 */
				channels = < 0x10 >;             /* in zephyr\dts\vendor\nordic\nrf54l_05_10_15.dtsi:285 */
				groups = < 0x6 >;                /* in zephyr\dts\vendor\nordic\nrf54l_05_10_15.dtsi:286 */
				status = "okay";                 /* in zephyr\dts\arm\nordic\nrf54l_05_10_15_cpuapp.dtsi:103 */
			};

			/* node '/soc/peripheral@50000000/ppib@c3000' defined in zephyr\dts\vendor\nordic\nrf54l_05_10_15.dtsi:289 */
			ppib20: ppib@c3000 {
				compatible = "nordic,nrf-ppib"; /* in zephyr\dts\vendor\nordic\nrf54l_05_10_15.dtsi:290 */
				reg = < 0xc3000 0x1000 >;       /* in zephyr\dts\vendor\nordic\nrf54l_05_10_15.dtsi:291 */
				channels = < 0x8 >;             /* in zephyr\dts\vendor\nordic\nrf54l_05_10_15.dtsi:293 */
				status = "okay";                /* in zephyr\dts\arm\nordic\nrf54l_05_10_15_cpuapp.dtsi:127 */
			};

			/* node '/soc/peripheral@50000000/ppib@c4000' defined in zephyr\dts\vendor\nordic\nrf54l_05_10_15.dtsi:296 */
			ppib21: ppib@c4000 {
				compatible = "nordic,nrf-ppib"; /* in zephyr\dts\vendor\nordic\nrf54l_05_10_15.dtsi:297 */
				reg = < 0xc4000 0x1000 >;       /* in zephyr\dts\vendor\nordic\nrf54l_05_10_15.dtsi:298 */
				channels = < 0x10 >;            /* in zephyr\dts\vendor\nordic\nrf54l_05_10_15.dtsi:300 */
				status = "okay";                /* in zephyr\dts\arm\nordic\nrf54l_05_10_15_cpuapp.dtsi:131 */
			};

			/* node '/soc/peripheral@50000000/ppib@c5000' defined in zephyr\dts\vendor\nordic\nrf54l_05_10_15.dtsi:303 */
			ppib22: ppib@c5000 {
				compatible = "nordic,nrf-ppib"; /* in zephyr\dts\vendor\nordic\nrf54l_05_10_15.dtsi:304 */
				reg = < 0xc5000 0x1000 >;       /* in zephyr\dts\vendor\nordic\nrf54l_05_10_15.dtsi:305 */
				channels = < 0x4 >;             /* in zephyr\dts\vendor\nordic\nrf54l_05_10_15.dtsi:307 */
				status = "okay";                /* in zephyr\dts\arm\nordic\nrf54l_05_10_15_cpuapp.dtsi:135 */
			};

			/* node '/soc/peripheral@50000000/i2c@c6000' defined in zephyr\dts\vendor\nordic\nrf54l_05_10_15.dtsi:310 */
			i2c20: i2c@c6000 {
				compatible = "nordic,nrf-twim";    /* in zephyr\dts\vendor\nordic\nrf54l_05_10_15.dtsi:311 */
				#address-cells = < 0x1 >;          /* in zephyr\dts\vendor\nordic\nrf54l_05_10_15.dtsi:312 */
				#size-cells = < 0x0 >;             /* in zephyr\dts\vendor\nordic\nrf54l_05_10_15.dtsi:313 */
				reg = < 0xc6000 0x1000 >;          /* in zephyr\dts\vendor\nordic\nrf54l_05_10_15.dtsi:314 */
				interrupts = < 0xc6 0x1 >;         /* in zephyr\dts\vendor\nordic\nrf54l_05_10_15.dtsi:315 */
				easydma-maxcnt-bits = < 0x10 >;    /* in zephyr\dts\vendor\nordic\nrf54l_05_10_15.dtsi:316 */
				clock-tolerance-percent = < 0x6 >; /* in zephyr\dts\vendor\nordic\nrf54l_05_10_15.dtsi:317 */
				status = "disabled";               /* in zephyr\dts\vendor\nordic\nrf54l_05_10_15.dtsi:318 */
				zephyr,pm-device-runtime-auto;     /* in zephyr\dts\vendor\nordic\nrf54l_05_10_15.dtsi:319 */
			};

			/* node '/soc/peripheral@50000000/spi@c6000' defined in zephyr\dts\vendor\nordic\nrf54l_05_10_15.dtsi:322 */
			spi20: spi@c6000 {
				compatible = "nordic,nrf-spim"; /* in zephyr\dts\vendor\nordic\nrf54l_05_10_15.dtsi:329 */
				#address-cells = < 0x1 >;       /* in zephyr\dts\vendor\nordic\nrf54l_05_10_15.dtsi:330 */
				#size-cells = < 0x0 >;          /* in zephyr\dts\vendor\nordic\nrf54l_05_10_15.dtsi:331 */
				reg = < 0xc6000 0x1000 >;       /* in zephyr\dts\vendor\nordic\nrf54l_05_10_15.dtsi:332 */
				interrupts = < 0xc6 0x1 >;      /* in zephyr\dts\vendor\nordic\nrf54l_05_10_15.dtsi:333 */
				max-frequency = < 0x7a1200 >;   /* in zephyr\dts\vendor\nordic\nrf54l_05_10_15.dtsi:334 */
				easydma-maxcnt-bits = < 0x10 >; /* in zephyr\dts\vendor\nordic\nrf54l_05_10_15.dtsi:335 */
				rx-delay-supported;             /* in zephyr\dts\vendor\nordic\nrf54l_05_10_15.dtsi:336 */
				rx-delay = < 0x1 >;             /* in zephyr\dts\vendor\nordic\nrf54l_05_10_15.dtsi:337 */
				status = "disabled";            /* in zephyr\dts\vendor\nordic\nrf54l_05_10_15.dtsi:338 */
			};

			/* node '/soc/peripheral@50000000/uart@c6000' defined in zephyr\dts\vendor\nordic\nrf54l_05_10_15.dtsi:341 */
			uart20: uart@c6000 {
				compatible = "nordic,nrf-uarte"; /* in zephyr\dts\vendor\nordic\nrf54l_05_10_15.dtsi:342 */
				reg = < 0xc6000 0x1000 >;        /* in zephyr\dts\vendor\nordic\nrf54l_05_10_15.dtsi:343 */
				interrupts = < 0xc6 0x1 >;       /* in zephyr\dts\vendor\nordic\nrf54l_05_10_15.dtsi:344 */
				status = "disabled";             /* in zephyr\dts\vendor\nordic\nrf54l_05_10_15.dtsi:345 */
				endtx-stoptx-supported;          /* in zephyr\dts\vendor\nordic\nrf54l_05_10_15.dtsi:346 */
				frame-timeout-supported;         /* in zephyr\dts\vendor\nordic\nrf54l_05_10_15.dtsi:347 */
			};

			/* node '/soc/peripheral@50000000/i2c@c7000' defined in zephyr\dts\vendor\nordic\nrf54l_05_10_15.dtsi:350 */
			i2c21: sys_i2c_peripheral: i2c@c7000 {
				#address-cells = < 0x1 >;          /* in zephyr\dts\vendor\nordic\nrf54l_05_10_15.dtsi:352 */
				#size-cells = < 0x0 >;             /* in zephyr\dts\vendor\nordic\nrf54l_05_10_15.dtsi:353 */
				reg = < 0xc7000 0x1000 >;          /* in zephyr\dts\vendor\nordic\nrf54l_05_10_15.dtsi:354 */
				interrupts = < 0xc7 0x1 >;         /* in zephyr\dts\vendor\nordic\nrf54l_05_10_15.dtsi:355 */
				easydma-maxcnt-bits = < 0x10 >;    /* in zephyr\dts\vendor\nordic\nrf54l_05_10_15.dtsi:356 */
				clock-tolerance-percent = < 0x6 >; /* in zephyr\dts\vendor\nordic\nrf54l_05_10_15.dtsi:357 */
				zephyr,pm-device-runtime-auto;     /* in zephyr\dts\vendor\nordic\nrf54l_05_10_15.dtsi:359 */
				status = "okay";                   /* in ..\..\Users\salamid1\AppData\Local\Temp\senswear_fig4a_1164e335\boards\SenseraTechnologies\SensWear\SensWear_nrf54l15_cpuapp.dts:204 */
				compatible = "nordic,nrf-twim";    /* in ..\..\Users\salamid1\AppData\Local\Temp\senswear_fig4a_1164e335\boards\SenseraTechnologies\SensWear\SensWear_nrf54l15_cpuapp.dts:205 */
				clock-frequency = < 0x186a0 >;     /* in ..\..\Users\salamid1\AppData\Local\Temp\senswear_fig4a_1164e335\boards\SenseraTechnologies\SensWear\SensWear_nrf54l15_cpuapp.dts:206 */
				pinctrl-0 = < &i2c21_default >;    /* in ..\..\Users\salamid1\AppData\Local\Temp\senswear_fig4a_1164e335\boards\SenseraTechnologies\SensWear\SensWear_nrf54l15_cpuapp.dts:207 */
				pinctrl-1 = < &i2c21_sleep >;      /* in ..\..\Users\salamid1\AppData\Local\Temp\senswear_fig4a_1164e335\boards\SenseraTechnologies\SensWear\SensWear_nrf54l15_cpuapp.dts:208 */
				pinctrl-names = "default",
				                "sleep";           /* in ..\..\Users\salamid1\AppData\Local\Temp\senswear_fig4a_1164e335\boards\SenseraTechnologies\SensWear\SensWear_nrf54l15_cpuapp.dts:209 */
				phandle = < 0x10 >;                /* in ..\..\Users\salamid1\AppData\Local\Temp\senswear_fig4a_1164e335\boards\SenseraTechnologies\SensWear\SensWear_nrf54l15_cpuapp.dts:32 */

				/* node '/soc/peripheral@50000000/i2c@c7000/lp5562@30' defined in ..\..\Users\salamid1\AppData\Local\Temp\senswear_fig4a_1164e335\boards\SenseraTechnologies\SensWear\SensWear_nrf54l15_cpuapp.dts:214 */
				lp5562: lp5562@30 {
					compatible = "ti,lp5562";          /* in ..\..\Users\salamid1\AppData\Local\Temp\senswear_fig4a_1164e335\boards\SenseraTechnologies\SensWear\SensWear_nrf54l15_cpuapp.dts:215 */
					reg = < 0x30 >;                    /* in ..\..\Users\salamid1\AppData\Local\Temp\senswear_fig4a_1164e335\boards\SenseraTechnologies\SensWear\SensWear_nrf54l15_cpuapp.dts:216 */
					enable-gpios = < &gpio1 0x4 0x0 >; /* in ..\..\Users\salamid1\AppData\Local\Temp\senswear_fig4a_1164e335\boards\SenseraTechnologies\SensWear\SensWear_nrf54l15_cpuapp.dts:217 */
					status = "okay";                   /* in ..\..\Users\salamid1\AppData\Local\Temp\senswear_fig4a_1164e335\boards\SenseraTechnologies\SensWear\SensWear_nrf54l15_cpuapp.dts:218 */
				};

				/* node '/soc/peripheral@50000000/i2c@c7000/fuel-gauge@55' defined in ..\..\Users\salamid1\AppData\Local\Temp\senswear_fig4a_1164e335\boards\SenseraTechnologies\SensWear\SensWear_nrf54l15_cpuapp.dts:224 */
				bq27427: fuel-gauge@55 {
					compatible = "senswear,bq27427"; /* in ..\..\Users\salamid1\AppData\Local\Temp\senswear_fig4a_1164e335\boards\SenseraTechnologies\SensWear\SensWear_nrf54l15_cpuapp.dts:225 */
					reg = < 0x55 >;                  /* in ..\..\Users\salamid1\AppData\Local\Temp\senswear_fig4a_1164e335\boards\SenseraTechnologies\SensWear\SensWear_nrf54l15_cpuapp.dts:226 */
					int-gpios = < &gpio1 0x7 0x1 >;  /* in ..\..\Users\salamid1\AppData\Local\Temp\senswear_fig4a_1164e335\boards\SenseraTechnologies\SensWear\SensWear_nrf54l15_cpuapp.dts:227 */
					status = "okay";                 /* in ..\..\Users\salamid1\AppData\Local\Temp\senswear_fig4a_1164e335\boards\SenseraTechnologies\SensWear\SensWear_nrf54l15_cpuapp.dts:228 */
				};

				/* node '/soc/peripheral@50000000/i2c@c7000/regulator@68' defined in ..\..\Users\salamid1\AppData\Local\Temp\senswear_fig4a_1164e335\boards\SenseraTechnologies\SensWear\SensWear_nrf54l15_cpuapp.dts:234 */
				tpsm83102: regulator@68 {
					compatible = "ti,tpsm83102";            /* in ..\..\Users\salamid1\AppData\Local\Temp\senswear_fig4a_1164e335\boards\SenseraTechnologies\SensWear\SensWear_nrf54l15_cpuapp.dts:235 */
					reg = < 0x68 >;                         /* in ..\..\Users\salamid1\AppData\Local\Temp\senswear_fig4a_1164e335\boards\SenseraTechnologies\SensWear\SensWear_nrf54l15_cpuapp.dts:236 */
					enable-gpios = < &gpio1 0x6 0x0 >;      /* in ..\..\Users\salamid1\AppData\Local\Temp\senswear_fig4a_1164e335\boards\SenseraTechnologies\SensWear\SensWear_nrf54l15_cpuapp.dts:237 */
					regulator-name = "VDD_DAUGHTER";        /* in ..\..\Users\salamid1\AppData\Local\Temp\senswear_fig4a_1164e335\boards\SenseraTechnologies\SensWear\SensWear_nrf54l15_cpuapp.dts:238 */
					regulator-min-microvolt = < 0xf4240 >;  /* in ..\..\Users\salamid1\AppData\Local\Temp\senswear_fig4a_1164e335\boards\SenseraTechnologies\SensWear\SensWear_nrf54l15_cpuapp.dts:239 */
					regulator-max-microvolt = < 0x53ec60 >; /* in ..\..\Users\salamid1\AppData\Local\Temp\senswear_fig4a_1164e335\boards\SenseraTechnologies\SensWear\SensWear_nrf54l15_cpuapp.dts:240 */
					status = "okay";                        /* in ..\..\Users\salamid1\AppData\Local\Temp\senswear_fig4a_1164e335\boards\SenseraTechnologies\SensWear\SensWear_nrf54l15_cpuapp.dts:241 */
				};

				/* node '/soc/peripheral@50000000/i2c@c7000/charger@6a' defined in ..\..\Users\salamid1\AppData\Local\Temp\senswear_fig4a_1164e335\boards\SenseraTechnologies\SensWear\SensWear_nrf54l15_cpuapp.dts:247 */
				bq25180: charger@6a {
					compatible = "senswear,bq25180"; /* in ..\..\Users\salamid1\AppData\Local\Temp\senswear_fig4a_1164e335\boards\SenseraTechnologies\SensWear\SensWear_nrf54l15_cpuapp.dts:248 */
					reg = < 0x6a >;                  /* in ..\..\Users\salamid1\AppData\Local\Temp\senswear_fig4a_1164e335\boards\SenseraTechnologies\SensWear\SensWear_nrf54l15_cpuapp.dts:249 */
					int-gpios = < &gpio1 0x5 0x1 >;  /* in ..\..\Users\salamid1\AppData\Local\Temp\senswear_fig4a_1164e335\boards\SenseraTechnologies\SensWear\SensWear_nrf54l15_cpuapp.dts:250 */
					kill-gpios = < &gpio1 0x8 0x7 >; /* in ..\..\Users\salamid1\AppData\Local\Temp\senswear_fig4a_1164e335\boards\SenseraTechnologies\SensWear\SensWear_nrf54l15_cpuapp.dts:256 */
					status = "okay";                 /* in ..\..\Users\salamid1\AppData\Local\Temp\senswear_fig4a_1164e335\boards\SenseraTechnologies\SensWear\SensWear_nrf54l15_cpuapp.dts:257 */
				};
			};

			/* node '/soc/peripheral@50000000/spi@c7000' defined in zephyr\dts\vendor\nordic\nrf54l_05_10_15.dtsi:362 */
			spi21: spi@c7000 {
				compatible = "nordic,nrf-spim"; /* in zephyr\dts\vendor\nordic\nrf54l_05_10_15.dtsi:369 */
				#address-cells = < 0x1 >;       /* in zephyr\dts\vendor\nordic\nrf54l_05_10_15.dtsi:370 */
				#size-cells = < 0x0 >;          /* in zephyr\dts\vendor\nordic\nrf54l_05_10_15.dtsi:371 */
				reg = < 0xc7000 0x1000 >;       /* in zephyr\dts\vendor\nordic\nrf54l_05_10_15.dtsi:372 */
				interrupts = < 0xc7 0x1 >;      /* in zephyr\dts\vendor\nordic\nrf54l_05_10_15.dtsi:373 */
				max-frequency = < 0x7a1200 >;   /* in zephyr\dts\vendor\nordic\nrf54l_05_10_15.dtsi:374 */
				easydma-maxcnt-bits = < 0x10 >; /* in zephyr\dts\vendor\nordic\nrf54l_05_10_15.dtsi:375 */
				rx-delay-supported;             /* in zephyr\dts\vendor\nordic\nrf54l_05_10_15.dtsi:376 */
				rx-delay = < 0x1 >;             /* in zephyr\dts\vendor\nordic\nrf54l_05_10_15.dtsi:377 */
				status = "disabled";            /* in zephyr\dts\vendor\nordic\nrf54l_05_10_15.dtsi:378 */
			};

			/* node '/soc/peripheral@50000000/uart@c7000' defined in zephyr\dts\vendor\nordic\nrf54l_05_10_15.dtsi:381 */
			uart21: uart@c7000 {
				compatible = "nordic,nrf-uarte"; /* in zephyr\dts\vendor\nordic\nrf54l_05_10_15.dtsi:382 */
				reg = < 0xc7000 0x1000 >;        /* in zephyr\dts\vendor\nordic\nrf54l_05_10_15.dtsi:383 */
				interrupts = < 0xc7 0x1 >;       /* in zephyr\dts\vendor\nordic\nrf54l_05_10_15.dtsi:384 */
				status = "disabled";             /* in zephyr\dts\vendor\nordic\nrf54l_05_10_15.dtsi:385 */
				endtx-stoptx-supported;          /* in zephyr\dts\vendor\nordic\nrf54l_05_10_15.dtsi:386 */
				frame-timeout-supported;         /* in zephyr\dts\vendor\nordic\nrf54l_05_10_15.dtsi:387 */
			};

			/* node '/soc/peripheral@50000000/i2c@c8000' defined in zephyr\dts\vendor\nordic\nrf54l_05_10_15.dtsi:390 */
			i2c22: i2c@c8000 {
				compatible = "nordic,nrf-twim";    /* in zephyr\dts\vendor\nordic\nrf54l_05_10_15.dtsi:391 */
				#address-cells = < 0x1 >;          /* in zephyr\dts\vendor\nordic\nrf54l_05_10_15.dtsi:392 */
				#size-cells = < 0x0 >;             /* in zephyr\dts\vendor\nordic\nrf54l_05_10_15.dtsi:393 */
				reg = < 0xc8000 0x1000 >;          /* in zephyr\dts\vendor\nordic\nrf54l_05_10_15.dtsi:394 */
				interrupts = < 0xc8 0x1 >;         /* in zephyr\dts\vendor\nordic\nrf54l_05_10_15.dtsi:395 */
				easydma-maxcnt-bits = < 0x10 >;    /* in zephyr\dts\vendor\nordic\nrf54l_05_10_15.dtsi:396 */
				clock-tolerance-percent = < 0x6 >; /* in zephyr\dts\vendor\nordic\nrf54l_05_10_15.dtsi:397 */
				status = "disabled";               /* in zephyr\dts\vendor\nordic\nrf54l_05_10_15.dtsi:398 */
				zephyr,pm-device-runtime-auto;     /* in zephyr\dts\vendor\nordic\nrf54l_05_10_15.dtsi:399 */
			};

			/* node '/soc/peripheral@50000000/spi@c8000' defined in zephyr\dts\vendor\nordic\nrf54l_05_10_15.dtsi:402 */
			spi22: spi@c8000 {
				compatible = "nordic,nrf-spim"; /* in zephyr\dts\vendor\nordic\nrf54l_05_10_15.dtsi:409 */
				#address-cells = < 0x1 >;       /* in zephyr\dts\vendor\nordic\nrf54l_05_10_15.dtsi:410 */
				#size-cells = < 0x0 >;          /* in zephyr\dts\vendor\nordic\nrf54l_05_10_15.dtsi:411 */
				reg = < 0xc8000 0x1000 >;       /* in zephyr\dts\vendor\nordic\nrf54l_05_10_15.dtsi:412 */
				interrupts = < 0xc8 0x1 >;      /* in zephyr\dts\vendor\nordic\nrf54l_05_10_15.dtsi:413 */
				max-frequency = < 0x7a1200 >;   /* in zephyr\dts\vendor\nordic\nrf54l_05_10_15.dtsi:414 */
				easydma-maxcnt-bits = < 0x10 >; /* in zephyr\dts\vendor\nordic\nrf54l_05_10_15.dtsi:415 */
				rx-delay-supported;             /* in zephyr\dts\vendor\nordic\nrf54l_05_10_15.dtsi:416 */
				rx-delay = < 0x1 >;             /* in zephyr\dts\vendor\nordic\nrf54l_05_10_15.dtsi:417 */
				status = "disabled";            /* in zephyr\dts\vendor\nordic\nrf54l_05_10_15.dtsi:418 */
			};

			/* node '/soc/peripheral@50000000/uart@c8000' defined in zephyr\dts\vendor\nordic\nrf54l_05_10_15.dtsi:421 */
			uart22: uart@c8000 {
				compatible = "nordic,nrf-uarte"; /* in zephyr\dts\vendor\nordic\nrf54l_05_10_15.dtsi:422 */
				reg = < 0xc8000 0x1000 >;        /* in zephyr\dts\vendor\nordic\nrf54l_05_10_15.dtsi:423 */
				interrupts = < 0xc8 0x1 >;       /* in zephyr\dts\vendor\nordic\nrf54l_05_10_15.dtsi:424 */
				status = "disabled";             /* in zephyr\dts\vendor\nordic\nrf54l_05_10_15.dtsi:425 */
				endtx-stoptx-supported;          /* in zephyr\dts\vendor\nordic\nrf54l_05_10_15.dtsi:426 */
				frame-timeout-supported;         /* in zephyr\dts\vendor\nordic\nrf54l_05_10_15.dtsi:427 */
			};

			/* node '/soc/peripheral@50000000/egu@c9000' defined in zephyr\dts\vendor\nordic\nrf54l_05_10_15.dtsi:430 */
			egu20: egu@c9000 {
				compatible = "nordic,nrf-egu"; /* in zephyr\dts\vendor\nordic\nrf54l_05_10_15.dtsi:431 */
				reg = < 0xc9000 0x1000 >;      /* in zephyr\dts\vendor\nordic\nrf54l_05_10_15.dtsi:432 */
				interrupts = < 0xc9 0x1 >;     /* in zephyr\dts\vendor\nordic\nrf54l_05_10_15.dtsi:433 */
				status = "disabled";           /* in zephyr\dts\vendor\nordic\nrf54l_05_10_15.dtsi:434 */
			};

			/* node '/soc/peripheral@50000000/timer@ca000' defined in zephyr\dts\vendor\nordic\nrf54l_05_10_15.dtsi:437 */
			timer20: timer@ca000 {
				compatible = "nordic,nrf-timer"; /* in zephyr\dts\vendor\nordic\nrf54l_05_10_15.dtsi:438 */
				status = "disabled";             /* in zephyr\dts\vendor\nordic\nrf54l_05_10_15.dtsi:439 */
				reg = < 0xca000 0x1000 >;        /* in zephyr\dts\vendor\nordic\nrf54l_05_10_15.dtsi:440 */
				cc-num = < 0x6 >;                /* in zephyr\dts\vendor\nordic\nrf54l_05_10_15.dtsi:441 */
				max-bit-width = < 0x20 >;        /* in zephyr\dts\vendor\nordic\nrf54l_05_10_15.dtsi:442 */
				interrupts = < 0xca 0x1 >;       /* in zephyr\dts\vendor\nordic\nrf54l_05_10_15.dtsi:443 */
				prescaler = < 0x0 >;             /* in zephyr\dts\vendor\nordic\nrf54l_05_10_15.dtsi:444 */
			};

			/* node '/soc/peripheral@50000000/timer@cb000' defined in zephyr\dts\vendor\nordic\nrf54l_05_10_15.dtsi:447 */
			timer21: timer@cb000 {
				compatible = "nordic,nrf-timer"; /* in zephyr\dts\vendor\nordic\nrf54l_05_10_15.dtsi:448 */
				status = "disabled";             /* in zephyr\dts\vendor\nordic\nrf54l_05_10_15.dtsi:449 */
				reg = < 0xcb000 0x1000 >;        /* in zephyr\dts\vendor\nordic\nrf54l_05_10_15.dtsi:450 */
				cc-num = < 0x6 >;                /* in zephyr\dts\vendor\nordic\nrf54l_05_10_15.dtsi:451 */
				max-bit-width = < 0x20 >;        /* in zephyr\dts\vendor\nordic\nrf54l_05_10_15.dtsi:452 */
				interrupts = < 0xcb 0x1 >;       /* in zephyr\dts\vendor\nordic\nrf54l_05_10_15.dtsi:453 */
				prescaler = < 0x0 >;             /* in zephyr\dts\vendor\nordic\nrf54l_05_10_15.dtsi:454 */
			};

			/* node '/soc/peripheral@50000000/timer@cc000' defined in zephyr\dts\vendor\nordic\nrf54l_05_10_15.dtsi:457 */
			timer22: timer@cc000 {
				compatible = "nordic,nrf-timer"; /* in zephyr\dts\vendor\nordic\nrf54l_05_10_15.dtsi:458 */
				status = "disabled";             /* in zephyr\dts\vendor\nordic\nrf54l_05_10_15.dtsi:459 */
				reg = < 0xcc000 0x1000 >;        /* in zephyr\dts\vendor\nordic\nrf54l_05_10_15.dtsi:460 */
				cc-num = < 0x6 >;                /* in zephyr\dts\vendor\nordic\nrf54l_05_10_15.dtsi:461 */
				max-bit-width = < 0x20 >;        /* in zephyr\dts\vendor\nordic\nrf54l_05_10_15.dtsi:462 */
				interrupts = < 0xcc 0x1 >;       /* in zephyr\dts\vendor\nordic\nrf54l_05_10_15.dtsi:463 */
				prescaler = < 0x0 >;             /* in zephyr\dts\vendor\nordic\nrf54l_05_10_15.dtsi:464 */
			};

			/* node '/soc/peripheral@50000000/timer@cd000' defined in zephyr\dts\vendor\nordic\nrf54l_05_10_15.dtsi:467 */
			timer23: timer@cd000 {
				compatible = "nordic,nrf-timer"; /* in zephyr\dts\vendor\nordic\nrf54l_05_10_15.dtsi:468 */
				status = "disabled";             /* in zephyr\dts\vendor\nordic\nrf54l_05_10_15.dtsi:469 */
				reg = < 0xcd000 0x1000 >;        /* in zephyr\dts\vendor\nordic\nrf54l_05_10_15.dtsi:470 */
				cc-num = < 0x6 >;                /* in zephyr\dts\vendor\nordic\nrf54l_05_10_15.dtsi:471 */
				max-bit-width = < 0x20 >;        /* in zephyr\dts\vendor\nordic\nrf54l_05_10_15.dtsi:472 */
				interrupts = < 0xcd 0x1 >;       /* in zephyr\dts\vendor\nordic\nrf54l_05_10_15.dtsi:473 */
				prescaler = < 0x0 >;             /* in zephyr\dts\vendor\nordic\nrf54l_05_10_15.dtsi:474 */
			};

			/* node '/soc/peripheral@50000000/timer@ce000' defined in zephyr\dts\vendor\nordic\nrf54l_05_10_15.dtsi:477 */
			timer24: timer@ce000 {
				compatible = "nordic,nrf-timer"; /* in zephyr\dts\vendor\nordic\nrf54l_05_10_15.dtsi:478 */
				status = "disabled";             /* in zephyr\dts\vendor\nordic\nrf54l_05_10_15.dtsi:479 */
				reg = < 0xce000 0x1000 >;        /* in zephyr\dts\vendor\nordic\nrf54l_05_10_15.dtsi:480 */
				cc-num = < 0x6 >;                /* in zephyr\dts\vendor\nordic\nrf54l_05_10_15.dtsi:481 */
				max-bit-width = < 0x20 >;        /* in zephyr\dts\vendor\nordic\nrf54l_05_10_15.dtsi:482 */
				interrupts = < 0xce 0x1 >;       /* in zephyr\dts\vendor\nordic\nrf54l_05_10_15.dtsi:483 */
				prescaler = < 0x0 >;             /* in zephyr\dts\vendor\nordic\nrf54l_05_10_15.dtsi:484 */
			};

			/* node '/soc/peripheral@50000000/pdm@d0000' defined in zephyr\dts\vendor\nordic\nrf54l_05_10_15.dtsi:487 */
			pdm20: pdm@d0000 {
				compatible = "nordic,nrf-pdm"; /* in zephyr\dts\vendor\nordic\nrf54l_05_10_15.dtsi:488 */
				status = "disabled";           /* in zephyr\dts\vendor\nordic\nrf54l_05_10_15.dtsi:489 */
				reg = < 0xd0000 0x1000 >;      /* in zephyr\dts\vendor\nordic\nrf54l_05_10_15.dtsi:490 */
				interrupts = < 0xd0 0x1 >;     /* in zephyr\dts\vendor\nordic\nrf54l_05_10_15.dtsi:491 */
			};

			/* node '/soc/peripheral@50000000/pdm@d1000' defined in zephyr\dts\vendor\nordic\nrf54l_05_10_15.dtsi:494 */
			pdm21: pdm@d1000 {
				compatible = "nordic,nrf-pdm"; /* in zephyr\dts\vendor\nordic\nrf54l_05_10_15.dtsi:495 */
				status = "disabled";           /* in zephyr\dts\vendor\nordic\nrf54l_05_10_15.dtsi:496 */
				reg = < 0xd1000 0x1000 >;      /* in zephyr\dts\vendor\nordic\nrf54l_05_10_15.dtsi:497 */
				interrupts = < 0xd1 0x1 >;     /* in zephyr\dts\vendor\nordic\nrf54l_05_10_15.dtsi:498 */
			};

			/* node '/soc/peripheral@50000000/pwm@d2000' defined in zephyr\dts\vendor\nordic\nrf54l_05_10_15.dtsi:501 */
			pwm20: pwm@d2000 {
				compatible = "nordic,nrf-pwm"; /* in zephyr\dts\vendor\nordic\nrf54l_05_10_15.dtsi:502 */
				status = "disabled";           /* in zephyr\dts\vendor\nordic\nrf54l_05_10_15.dtsi:503 */
				reg = < 0xd2000 0x1000 >;      /* in zephyr\dts\vendor\nordic\nrf54l_05_10_15.dtsi:504 */
				interrupts = < 0xd2 0x1 >;     /* in zephyr\dts\vendor\nordic\nrf54l_05_10_15.dtsi:505 */
				#pwm-cells = < 0x3 >;          /* in zephyr\dts\vendor\nordic\nrf54l_05_10_15.dtsi:506 */
				idleout-supported;             /* in zephyr\dts\vendor\nordic\nrf54l_05_10_15.dtsi:507 */
			};

			/* node '/soc/peripheral@50000000/pwm@d3000' defined in zephyr\dts\vendor\nordic\nrf54l_05_10_15.dtsi:510 */
			pwm21: pwm@d3000 {
				compatible = "nordic,nrf-pwm"; /* in zephyr\dts\vendor\nordic\nrf54l_05_10_15.dtsi:511 */
				status = "disabled";           /* in zephyr\dts\vendor\nordic\nrf54l_05_10_15.dtsi:512 */
				reg = < 0xd3000 0x1000 >;      /* in zephyr\dts\vendor\nordic\nrf54l_05_10_15.dtsi:513 */
				interrupts = < 0xd3 0x1 >;     /* in zephyr\dts\vendor\nordic\nrf54l_05_10_15.dtsi:514 */
				#pwm-cells = < 0x3 >;          /* in zephyr\dts\vendor\nordic\nrf54l_05_10_15.dtsi:515 */
				idleout-supported;             /* in zephyr\dts\vendor\nordic\nrf54l_05_10_15.dtsi:516 */
			};

			/* node '/soc/peripheral@50000000/pwm@d4000' defined in zephyr\dts\vendor\nordic\nrf54l_05_10_15.dtsi:519 */
			pwm22: pwm@d4000 {
				compatible = "nordic,nrf-pwm"; /* in zephyr\dts\vendor\nordic\nrf54l_05_10_15.dtsi:520 */
				status = "disabled";           /* in zephyr\dts\vendor\nordic\nrf54l_05_10_15.dtsi:521 */
				reg = < 0xd4000 0x1000 >;      /* in zephyr\dts\vendor\nordic\nrf54l_05_10_15.dtsi:522 */
				interrupts = < 0xd4 0x1 >;     /* in zephyr\dts\vendor\nordic\nrf54l_05_10_15.dtsi:523 */
				#pwm-cells = < 0x3 >;          /* in zephyr\dts\vendor\nordic\nrf54l_05_10_15.dtsi:524 */
				idleout-supported;             /* in zephyr\dts\vendor\nordic\nrf54l_05_10_15.dtsi:525 */
			};

			/* node '/soc/peripheral@50000000/adc@d5000' defined in zephyr\dts\vendor\nordic\nrf54l_05_10_15.dtsi:528 */
			adc: adc@d5000 {
				compatible = "nordic,nrf-saadc"; /* in zephyr\dts\vendor\nordic\nrf54l_05_10_15.dtsi:529 */
				reg = < 0xd5000 0x1000 >;        /* in zephyr\dts\vendor\nordic\nrf54l_05_10_15.dtsi:530 */
				interrupts = < 0xd5 0x1 >;       /* in zephyr\dts\vendor\nordic\nrf54l_05_10_15.dtsi:531 */
				status = "disabled";             /* in zephyr\dts\vendor\nordic\nrf54l_05_10_15.dtsi:532 */
				#io-channel-cells = < 0x1 >;     /* in zephyr\dts\vendor\nordic\nrf54l_05_10_15.dtsi:533 */
				zephyr,pm-device-runtime-auto;   /* in zephyr\dts\vendor\nordic\nrf54l_05_10_15.dtsi:534 */
			};

			/* node '/soc/peripheral@50000000/nfct@d6000' defined in zephyr\dts\vendor\nordic\nrf54l_05_10_15.dtsi:537 */
			nfct: nfct@d6000 {
				compatible = "nordic,nrf-nfct-v2"; /* in zephyr\dts\vendor\nordic\nrf54l_05_10_15.dtsi:538 */
				reg = < 0xd6000 0x1000 >;          /* in zephyr\dts\vendor\nordic\nrf54l_05_10_15.dtsi:539 */
				interrupts = < 0xd6 0x1 >;         /* in zephyr\dts\vendor\nordic\nrf54l_05_10_15.dtsi:540 */
				status = "disabled";               /* in zephyr\dts\vendor\nordic\nrf54l_05_10_15.dtsi:541 */
			};

			/* node '/soc/peripheral@50000000/temp@d7000' defined in zephyr\dts\vendor\nordic\nrf54l_05_10_15.dtsi:544 */
			temp: temp@d7000 {
				compatible = "nordic,nrf-temp"; /* in zephyr\dts\vendor\nordic\nrf54l_05_10_15.dtsi:545 */
				reg = < 0xd7000 0x1000 >;       /* in zephyr\dts\vendor\nordic\nrf54l_05_10_15.dtsi:546 */
				interrupts = < 0xd7 0x1 >;      /* in zephyr\dts\vendor\nordic\nrf54l_05_10_15.dtsi:547 */
				status = "disabled";            /* in zephyr\dts\vendor\nordic\nrf54l_05_10_15.dtsi:548 */
			};

			/* node '/soc/peripheral@50000000/gpio@d8200' defined in zephyr\dts\vendor\nordic\nrf54l_05_10_15.dtsi:551 */
			gpio1: gpio@d8200 {
				compatible = "nordic,nrf-gpio";  /* in zephyr\dts\vendor\nordic\nrf54l_05_10_15.dtsi:552 */
				gpio-controller;                 /* in zephyr\dts\vendor\nordic\nrf54l_05_10_15.dtsi:553 */
				reg = < 0xd8200 0x300 >;         /* in zephyr\dts\vendor\nordic\nrf54l_05_10_15.dtsi:554 */
				#gpio-cells = < 0x2 >;           /* in zephyr\dts\vendor\nordic\nrf54l_05_10_15.dtsi:555 */
				ngpios = < 0x11 >;               /* in zephyr\dts\vendor\nordic\nrf54l_05_10_15.dtsi:556 */
				port = < 0x1 >;                  /* in zephyr\dts\vendor\nordic\nrf54l_05_10_15.dtsi:558 */
				gpiote-instance = < &gpiote20 >; /* in zephyr\dts\vendor\nordic\nrf54l_05_10_15.dtsi:559 */
				status = "okay";                 /* in ..\..\Users\salamid1\AppData\Local\Temp\senswear_fig4a_1164e335\boards\SenseraTechnologies\SensWear\SensWear_nrf54l15_cpuapp.dts:262 */
				phandle = < 0x6 >;               /* in ..\..\Users\salamid1\AppData\Local\Temp\senswear_fig4a_1164e335\boards\SenseraTechnologies\SensWear\SensWear_nrf54l15_cpuapp.dts:344 */

				/* node '/soc/peripheral@50000000/gpio@d8200/lp5562_en_hog' defined in ..\..\Users\salamid1\AppData\Local\Temp\senswear_fig4a_1164e335\boards\SenseraTechnologies\SensWear\SensWear_nrf54l15_cpuapp.dts:267 */
				lp5562_en_hog: lp5562_en_hog {
					gpio-hog;                /* in ..\..\Users\salamid1\AppData\Local\Temp\senswear_fig4a_1164e335\boards\SenseraTechnologies\SensWear\SensWear_nrf54l15_cpuapp.dts:268 */
					gpios = < 0x4 0x1 >;     /* in ..\..\Users\salamid1\AppData\Local\Temp\senswear_fig4a_1164e335\boards\SenseraTechnologies\SensWear\SensWear_nrf54l15_cpuapp.dts:269 */
					output-high;             /* in ..\..\Users\salamid1\AppData\Local\Temp\senswear_fig4a_1164e335\boards\SenseraTechnologies\SensWear\SensWear_nrf54l15_cpuapp.dts:270 */
					line-name = "LP5562_EN"; /* in ..\..\Users\salamid1\AppData\Local\Temp\senswear_fig4a_1164e335\boards\SenseraTechnologies\SensWear\SensWear_nrf54l15_cpuapp.dts:271 */
				};

				/* node '/soc/peripheral@50000000/gpio@d8200/bq25180_pwr_kill_hog' defined in ..\..\Users\salamid1\AppData\Local\Temp\senswear_fig4a_1164e335\boards\SenseraTechnologies\SensWear\SensWear_nrf54l15_cpuapp.dts:284 */
				bq25180_pwr_kill_hog: bq25180_pwr_kill_hog {
					gpio-hog;               /* in ..\..\Users\salamid1\AppData\Local\Temp\senswear_fig4a_1164e335\boards\SenseraTechnologies\SensWear\SensWear_nrf54l15_cpuapp.dts:285 */
					gpios = < 0x8 0x6 >;    /* in ..\..\Users\salamid1\AppData\Local\Temp\senswear_fig4a_1164e335\boards\SenseraTechnologies\SensWear\SensWear_nrf54l15_cpuapp.dts:286 */
					output-high;            /* in ..\..\Users\salamid1\AppData\Local\Temp\senswear_fig4a_1164e335\boards\SenseraTechnologies\SensWear\SensWear_nrf54l15_cpuapp.dts:287 */
					line-name = "PWR_KILL"; /* in ..\..\Users\salamid1\AppData\Local\Temp\senswear_fig4a_1164e335\boards\SenseraTechnologies\SensWear\SensWear_nrf54l15_cpuapp.dts:288 */
				};

				/* node '/soc/peripheral@50000000/gpio@d8200/tpsm83102_en_hog' defined in ..\..\Users\salamid1\AppData\Local\Temp\senswear_fig4a_1164e335\boards\SenseraTechnologies\SensWear\SensWear_nrf54l15_cpuapp.dts:294 */
				tpsm83102_en_hog: tpsm83102_en_hog {
					gpio-hog;              /* in ..\..\Users\salamid1\AppData\Local\Temp\senswear_fig4a_1164e335\boards\SenseraTechnologies\SensWear\SensWear_nrf54l15_cpuapp.dts:295 */
					gpios = < 0x6 0x1 >;   /* in ..\..\Users\salamid1\AppData\Local\Temp\senswear_fig4a_1164e335\boards\SenseraTechnologies\SensWear\SensWear_nrf54l15_cpuapp.dts:296 */
					output-high;           /* in ..\..\Users\salamid1\AppData\Local\Temp\senswear_fig4a_1164e335\boards\SenseraTechnologies\SensWear\SensWear_nrf54l15_cpuapp.dts:297 */
					line-name = "VREG_EN"; /* in ..\..\Users\salamid1\AppData\Local\Temp\senswear_fig4a_1164e335\boards\SenseraTechnologies\SensWear\SensWear_nrf54l15_cpuapp.dts:298 */
				};
			};

			/* node '/soc/peripheral@50000000/gpiote@da000' defined in zephyr\dts\vendor\nordic\nrf54l_05_10_15.dtsi:562 */
			gpiote20: gpiote@da000 {
				compatible = "nordic,nrf-gpiote"; /* in zephyr\dts\vendor\nordic\nrf54l_05_10_15.dtsi:563 */
				reg = < 0xda000 0x1000 >;         /* in zephyr\dts\vendor\nordic\nrf54l_05_10_15.dtsi:564 */
				instance = < 0x14 >;              /* in zephyr\dts\vendor\nordic\nrf54l_05_10_15.dtsi:566 */
				interrupts = < 0xdb 0x1 >;        /* in zephyr\dts\arm\nordic\nrf54l_05_10_15_cpuapp.dtsi:82 */
				status = "okay";                  /* in ..\..\Users\salamid1\AppData\Local\Temp\senswear_fig4a_1164e335\boards\SenseraTechnologies\SensWear\SensWear_nrf54l15_cpuapp.dts:108 */
				phandle = < 0xa >;                /* in zephyr\dts\vendor\nordic\nrf54l_05_10_15.dtsi:559 */
			};

			/* node '/soc/peripheral@50000000/i2s@dd000' defined in zephyr\dts\vendor\nordic\nrf54l_05_10_15.dtsi:569 */
			i2s20: i2s@dd000 {
				compatible = "nordic,nrf-i2s"; /* in zephyr\dts\vendor\nordic\nrf54l_05_10_15.dtsi:570 */
				#address-cells = < 0x1 >;      /* in zephyr\dts\vendor\nordic\nrf54l_05_10_15.dtsi:571 */
				#size-cells = < 0x0 >;         /* in zephyr\dts\vendor\nordic\nrf54l_05_10_15.dtsi:572 */
				reg = < 0xdd000 0x1000 >;      /* in zephyr\dts\vendor\nordic\nrf54l_05_10_15.dtsi:573 */
				interrupts = < 0xdd 0x1 >;     /* in zephyr\dts\vendor\nordic\nrf54l_05_10_15.dtsi:574 */
				status = "disabled";           /* in zephyr\dts\vendor\nordic\nrf54l_05_10_15.dtsi:575 */
			};

			/* node '/soc/peripheral@50000000/qdec@e0000' defined in zephyr\dts\vendor\nordic\nrf54l_05_10_15.dtsi:578 */
			qdec20: qdec@e0000 {
				compatible = "nordic,nrf-qdec"; /* in zephyr\dts\vendor\nordic\nrf54l_05_10_15.dtsi:579 */
				reg = < 0xe0000 0x1000 >;       /* in zephyr\dts\vendor\nordic\nrf54l_05_10_15.dtsi:580 */
				interrupts = < 0xe0 0x1 >;      /* in zephyr\dts\vendor\nordic\nrf54l_05_10_15.dtsi:581 */
				status = "disabled";            /* in zephyr\dts\vendor\nordic\nrf54l_05_10_15.dtsi:582 */
			};

			/* node '/soc/peripheral@50000000/qdec@e1000' defined in zephyr\dts\vendor\nordic\nrf54l_05_10_15.dtsi:585 */
			qdec21: qdec@e1000 {
				compatible = "nordic,nrf-qdec"; /* in zephyr\dts\vendor\nordic\nrf54l_05_10_15.dtsi:586 */
				reg = < 0xe1000 0x1000 >;       /* in zephyr\dts\vendor\nordic\nrf54l_05_10_15.dtsi:587 */
				interrupts = < 0xe1 0x1 >;      /* in zephyr\dts\vendor\nordic\nrf54l_05_10_15.dtsi:588 */
				status = "disabled";            /* in zephyr\dts\vendor\nordic\nrf54l_05_10_15.dtsi:589 */
			};

			/* node '/soc/peripheral@50000000/grtc@e2000' defined in zephyr\dts\vendor\nordic\nrf54l_05_10_15.dtsi:592 */
			grtc: grtc@e2000 {
				compatible = "nordic,nrf-grtc";                                       /* in zephyr\dts\vendor\nordic\nrf54l_05_10_15.dtsi:593 */
				reg = < 0xe2000 0x1000 >;                                             /* in zephyr\dts\vendor\nordic\nrf54l_05_10_15.dtsi:594 */
				cc-num = < 0xc >;                                                     /* in zephyr\dts\vendor\nordic\nrf54l_05_10_15.dtsi:595 */
				clocks = < &lfxo >,
				         < &pclk >;                                                   /* in zephyr\dts\vendor\nordic\nrf54l_05_10_15.dtsi:596 */
				clock-names = "lfclock",
				              "hfclock";                                              /* in zephyr\dts\vendor\nordic\nrf54l_05_10_15.dtsi:597 */
				extended-channels = < 0x0 >;                                          /* in zephyr\dts\vendor\nordic\nrf54l_05_10_15.dtsi:599 */
				interrupts = < 0xe4 0x1 >,
				             < 0xe5 0x1 >;                                            /* in zephyr\dts\arm\nordic\nrf54l_05_10_15_cpuapp.dtsi:73 */
				owned-channels = < 0x0 0x1 0x2 0x3 0x4 0x5 0x6 0x7 0x8 0x9 0xa 0xb >; /* in ..\..\Users\salamid1\AppData\Local\Temp\senswear_fig4a_1164e335\boards\SenseraTechnologies\SensWear\SensWear_nrf54l15_cpuapp.dts:91 */
				child-owned-channels = < 0x3 0x4 0x7 0x8 0x9 0xa 0xb >;               /* in ..\..\Users\salamid1\AppData\Local\Temp\senswear_fig4a_1164e335\boards\SenseraTechnologies\SensWear\SensWear_nrf54l15_cpuapp.dts:95 */
				status = "okay";                                                      /* in ..\..\Users\salamid1\AppData\Local\Temp\senswear_fig4a_1164e335\boards\SenseraTechnologies\SensWear\SensWear_nrf54l15_cpuapp.dts:96 */
			};

			/* node '/soc/peripheral@50000000/dppic@102000' defined in zephyr\dts\vendor\nordic\nrf54l_05_10_15.dtsi:602 */
			dppic30: dppic@102000 {
				compatible = "nordic,nrf-dppic"; /* in zephyr\dts\vendor\nordic\nrf54l_05_10_15.dtsi:603 */
				reg = < 0x102000 0x808 >;        /* in zephyr\dts\vendor\nordic\nrf54l_05_10_15.dtsi:604 */
				channels = < 0x4 >;              /* in zephyr\dts\vendor\nordic\nrf54l_05_10_15.dtsi:606 */
				groups = < 0x2 >;                /* in zephyr\dts\vendor\nordic\nrf54l_05_10_15.dtsi:607 */
				status = "okay";                 /* in zephyr\dts\arm\nordic\nrf54l_05_10_15_cpuapp.dtsi:107 */
			};

			/* node '/soc/peripheral@50000000/ppib@103000' defined in zephyr\dts\vendor\nordic\nrf54l_05_10_15.dtsi:610 */
			ppib30: ppib@103000 {
				compatible = "nordic,nrf-ppib"; /* in zephyr\dts\vendor\nordic\nrf54l_05_10_15.dtsi:611 */
				reg = < 0x103000 0x1000 >;      /* in zephyr\dts\vendor\nordic\nrf54l_05_10_15.dtsi:612 */
				channels = < 0x4 >;             /* in zephyr\dts\vendor\nordic\nrf54l_05_10_15.dtsi:614 */
				status = "okay";                /* in zephyr\dts\arm\nordic\nrf54l_05_10_15_cpuapp.dtsi:139 */
			};

			/* node '/soc/peripheral@50000000/i2c@104000' defined in zephyr\dts\vendor\nordic\nrf54l_05_10_15.dtsi:617 */
			i2c30: i2c@104000 {
				compatible = "nordic,nrf-twim";    /* in zephyr\dts\vendor\nordic\nrf54l_05_10_15.dtsi:618 */
				#address-cells = < 0x1 >;          /* in zephyr\dts\vendor\nordic\nrf54l_05_10_15.dtsi:619 */
				#size-cells = < 0x0 >;             /* in zephyr\dts\vendor\nordic\nrf54l_05_10_15.dtsi:620 */
				reg = < 0x104000 0x1000 >;         /* in zephyr\dts\vendor\nordic\nrf54l_05_10_15.dtsi:621 */
				interrupts = < 0x104 0x1 >;        /* in zephyr\dts\vendor\nordic\nrf54l_05_10_15.dtsi:622 */
				easydma-maxcnt-bits = < 0x10 >;    /* in zephyr\dts\vendor\nordic\nrf54l_05_10_15.dtsi:623 */
				clock-tolerance-percent = < 0x6 >; /* in zephyr\dts\vendor\nordic\nrf54l_05_10_15.dtsi:624 */
				status = "disabled";               /* in zephyr\dts\vendor\nordic\nrf54l_05_10_15.dtsi:625 */
				zephyr,pm-device-runtime-auto;     /* in zephyr\dts\vendor\nordic\nrf54l_05_10_15.dtsi:626 */
			};

			/* node '/soc/peripheral@50000000/spi@104000' defined in zephyr\dts\vendor\nordic\nrf54l_05_10_15.dtsi:629 */
			spi30: spi@104000 {
				compatible = "nordic,nrf-spim"; /* in zephyr\dts\vendor\nordic\nrf54l_05_10_15.dtsi:636 */
				#address-cells = < 0x1 >;       /* in zephyr\dts\vendor\nordic\nrf54l_05_10_15.dtsi:637 */
				#size-cells = < 0x0 >;          /* in zephyr\dts\vendor\nordic\nrf54l_05_10_15.dtsi:638 */
				reg = < 0x104000 0x1000 >;      /* in zephyr\dts\vendor\nordic\nrf54l_05_10_15.dtsi:639 */
				interrupts = < 0x104 0x1 >;     /* in zephyr\dts\vendor\nordic\nrf54l_05_10_15.dtsi:640 */
				max-frequency = < 0x7a1200 >;   /* in zephyr\dts\vendor\nordic\nrf54l_05_10_15.dtsi:641 */
				easydma-maxcnt-bits = < 0x10 >; /* in zephyr\dts\vendor\nordic\nrf54l_05_10_15.dtsi:642 */
				rx-delay-supported;             /* in zephyr\dts\vendor\nordic\nrf54l_05_10_15.dtsi:643 */
				rx-delay = < 0x1 >;             /* in zephyr\dts\vendor\nordic\nrf54l_05_10_15.dtsi:644 */
				status = "disabled";            /* in zephyr\dts\vendor\nordic\nrf54l_05_10_15.dtsi:645 */
			};

			/* node '/soc/peripheral@50000000/uart@104000' defined in zephyr\dts\vendor\nordic\nrf54l_05_10_15.dtsi:648 */
			uart30: uart@104000 {
				compatible = "nordic,nrf-uarte"; /* in zephyr\dts\vendor\nordic\nrf54l_05_10_15.dtsi:649 */
				reg = < 0x104000 0x1000 >;       /* in zephyr\dts\vendor\nordic\nrf54l_05_10_15.dtsi:650 */
				interrupts = < 0x104 0x1 >;      /* in zephyr\dts\vendor\nordic\nrf54l_05_10_15.dtsi:651 */
				endtx-stoptx-supported;          /* in zephyr\dts\vendor\nordic\nrf54l_05_10_15.dtsi:653 */
				frame-timeout-supported;         /* in zephyr\dts\vendor\nordic\nrf54l_05_10_15.dtsi:654 */
				status = "okay";                 /* in ..\..\Users\salamid1\AppData\Local\Temp\senswear_fig4a_1164e335\boards\SenseraTechnologies\SensWear\SensWear_nrf54l15_cpuapp.dts:82 */
				current-speed = < 0xe1000 >;     /* in ..\..\Users\salamid1\AppData\Local\Temp\senswear_fig4a_1164e335\boards\SenseraTechnologies\SensWear\SensWear_nrf54l15_cpuapp.dts:83 */
				pinctrl-0 = < &uart30_default >; /* in ..\..\Users\salamid1\AppData\Local\Temp\senswear_fig4a_1164e335\boards\SenseraTechnologies\SensWear\SensWear_nrf54l15_cpuapp.dts:85 */
				pinctrl-1 = < &uart30_sleep >;   /* in ..\..\Users\salamid1\AppData\Local\Temp\senswear_fig4a_1164e335\boards\SenseraTechnologies\SensWear\SensWear_nrf54l15_cpuapp.dts:86 */
				pinctrl-names = "default",
				                "sleep";         /* in ..\..\Users\salamid1\AppData\Local\Temp\senswear_fig4a_1164e335\boards\SenseraTechnologies\SensWear\SensWear_nrf54l15_cpuapp.dts:87 */
			};

			/* node '/soc/peripheral@50000000/clock@10e000' defined in zephyr\dts\vendor\nordic\nrf54l_05_10_15.dtsi:657 */
			clock: clock@10e000 {
				compatible = "nordic,nrf-clock"; /* in zephyr\dts\vendor\nordic\nrf54l_05_10_15.dtsi:658 */
				reg = < 0x10e000 0x1000 >;       /* in zephyr\dts\vendor\nordic\nrf54l_05_10_15.dtsi:659 */
				interrupts = < 0x105 0x1 >;      /* in zephyr\dts\vendor\nordic\nrf54l_05_10_15.dtsi:660 */
				status = "okay";                 /* in ..\..\Users\salamid1\AppData\Local\Temp\senswear_fig4a_1164e335\boards\SenseraTechnologies\SensWear\SensWear_nrf54l15_cpuapp.dts:104 */
			};

			/* node '/soc/peripheral@50000000/power@10e000' defined in zephyr\dts\vendor\nordic\nrf54l_05_10_15.dtsi:664 */
			power: power@10e000 {
				compatible = "nordic,nrf-power";  /* in zephyr\dts\vendor\nordic\nrf54l_05_10_15.dtsi:665 */
				reg = < 0x10e000 0x1000 >;        /* in zephyr\dts\vendor\nordic\nrf54l_05_10_15.dtsi:666 */
				ranges = < 0x0 0x10e000 0x1000 >; /* in zephyr\dts\vendor\nordic\nrf54l_05_10_15.dtsi:667 */
				interrupts = < 0x105 0x1 >;       /* in zephyr\dts\vendor\nordic\nrf54l_05_10_15.dtsi:668 */
				status = "disabled";              /* in zephyr\dts\vendor\nordic\nrf54l_05_10_15.dtsi:669 */
				#address-cells = < 0x1 >;         /* in zephyr\dts\vendor\nordic\nrf54l_05_10_15.dtsi:670 */
				#size-cells = < 0x1 >;            /* in zephyr\dts\vendor\nordic\nrf54l_05_10_15.dtsi:671 */

				/* node '/soc/peripheral@50000000/power@10e000/gpregret1@500' defined in zephyr\dts\vendor\nordic\nrf54l_05_10_15.dtsi:673 */
				gpregret1: gpregret1@500 {
					#address-cells = < 0x1 >;           /* in zephyr\dts\vendor\nordic\nrf54l_05_10_15.dtsi:674 */
					#size-cells = < 0x1 >;              /* in zephyr\dts\vendor\nordic\nrf54l_05_10_15.dtsi:675 */
					compatible = "nordic,nrf-gpregret"; /* in zephyr\dts\vendor\nordic\nrf54l_05_10_15.dtsi:676 */
					reg = < 0x500 0x1 >;                /* in zephyr\dts\vendor\nordic\nrf54l_05_10_15.dtsi:677 */
					status = "disabled";                /* in zephyr\dts\vendor\nordic\nrf54l_05_10_15.dtsi:678 */
				};

				/* node '/soc/peripheral@50000000/power@10e000/gpregret2@504' defined in zephyr\dts\vendor\nordic\nrf54l_05_10_15.dtsi:681 */
				gpregret2: gpregret2@504 {
					#address-cells = < 0x1 >;           /* in zephyr\dts\vendor\nordic\nrf54l_05_10_15.dtsi:682 */
					#size-cells = < 0x1 >;              /* in zephyr\dts\vendor\nordic\nrf54l_05_10_15.dtsi:683 */
					compatible = "nordic,nrf-gpregret"; /* in zephyr\dts\vendor\nordic\nrf54l_05_10_15.dtsi:684 */
					reg = < 0x504 0x1 >;                /* in zephyr\dts\vendor\nordic\nrf54l_05_10_15.dtsi:685 */
					status = "disabled";                /* in zephyr\dts\vendor\nordic\nrf54l_05_10_15.dtsi:686 */
				};
			};

			/* node '/soc/peripheral@50000000/comparator@106000' defined in zephyr\dts\vendor\nordic\nrf54l_05_10_15.dtsi:690 */
			comp: comparator@106000 {
				compatible = "nordic,nrf-comp"; /* in zephyr\dts\vendor\nordic\nrf54l_05_10_15.dtsi:695 */
				reg = < 0x106000 0x1000 >;      /* in zephyr\dts\vendor\nordic\nrf54l_05_10_15.dtsi:696 */
				status = "disabled";            /* in zephyr\dts\vendor\nordic\nrf54l_05_10_15.dtsi:697 */
				interrupts = < 0x106 0x1 >;     /* in zephyr\dts\vendor\nordic\nrf54l_05_10_15.dtsi:698 */
			};

			/* node '/soc/peripheral@50000000/watchdog@108000' defined in zephyr\dts\vendor\nordic\nrf54l_05_10_15.dtsi:704 */
			wdt30: watchdog@108000 {
				compatible = "nordic,nrf-wdt"; /* in zephyr\dts\vendor\nordic\nrf54l_05_10_15.dtsi:705 */
				reg = < 0x108000 0x620 >;      /* in zephyr\dts\vendor\nordic\nrf54l_05_10_15.dtsi:706 */
				interrupts = < 0x108 0x1 >;    /* in zephyr\dts\vendor\nordic\nrf54l_05_10_15.dtsi:707 */
				status = "disabled";           /* in zephyr\dts\vendor\nordic\nrf54l_05_10_15.dtsi:708 */
			};

			/* node '/soc/peripheral@50000000/watchdog@109000' defined in zephyr\dts\vendor\nordic\nrf54l_05_10_15.dtsi:712 */
			wdt31: watchdog@109000 {
				compatible = "nordic,nrf-wdt"; /* in zephyr\dts\vendor\nordic\nrf54l_05_10_15.dtsi:713 */
				reg = < 0x109000 0x620 >;      /* in zephyr\dts\vendor\nordic\nrf54l_05_10_15.dtsi:714 */
				interrupts = < 0x109 0x1 >;    /* in zephyr\dts\vendor\nordic\nrf54l_05_10_15.dtsi:715 */
				status = "disabled";           /* in zephyr\dts\vendor\nordic\nrf54l_05_10_15.dtsi:716 */
			};

			/* node '/soc/peripheral@50000000/gpio@10a000' defined in zephyr\dts\vendor\nordic\nrf54l_05_10_15.dtsi:719 */
			gpio0: gpio@10a000 {
				compatible = "nordic,nrf-gpio";  /* in zephyr\dts\vendor\nordic\nrf54l_05_10_15.dtsi:720 */
				gpio-controller;                 /* in zephyr\dts\vendor\nordic\nrf54l_05_10_15.dtsi:721 */
				reg = < 0x10a000 0x300 >;        /* in zephyr\dts\vendor\nordic\nrf54l_05_10_15.dtsi:722 */
				#gpio-cells = < 0x2 >;           /* in zephyr\dts\vendor\nordic\nrf54l_05_10_15.dtsi:723 */
				ngpios = < 0x7 >;                /* in zephyr\dts\vendor\nordic\nrf54l_05_10_15.dtsi:724 */
				port = < 0x0 >;                  /* in zephyr\dts\vendor\nordic\nrf54l_05_10_15.dtsi:726 */
				gpiote-instance = < &gpiote30 >; /* in zephyr\dts\vendor\nordic\nrf54l_05_10_15.dtsi:727 */
				status = "okay";                 /* in ..\..\Users\salamid1\AppData\Local\Temp\senswear_fig4a_1164e335\boards\SenseraTechnologies\SensWear\SensWear_nrf54l15_cpuapp.dts:116 */
			};

			/* node '/soc/peripheral@50000000/gpiote@10c000' defined in zephyr\dts\vendor\nordic\nrf54l_05_10_15.dtsi:730 */
			gpiote30: gpiote@10c000 {
				compatible = "nordic,nrf-gpiote"; /* in zephyr\dts\vendor\nordic\nrf54l_05_10_15.dtsi:731 */
				reg = < 0x10c000 0x1000 >;        /* in zephyr\dts\vendor\nordic\nrf54l_05_10_15.dtsi:732 */
				instance = < 0x1e >;              /* in zephyr\dts\vendor\nordic\nrf54l_05_10_15.dtsi:734 */
				interrupts = < 0x10d 0x1 >;       /* in zephyr\dts\arm\nordic\nrf54l_05_10_15_cpuapp.dtsi:90 */
				status = "okay";                  /* in ..\..\Users\salamid1\AppData\Local\Temp\senswear_fig4a_1164e335\boards\SenseraTechnologies\SensWear\SensWear_nrf54l15_cpuapp.dts:112 */
				phandle = < 0xf >;                /* in zephyr\dts\vendor\nordic\nrf54l_05_10_15.dtsi:727 */
			};

			/* node '/soc/peripheral@50000000/regulator@120000' defined in zephyr\dts\vendor\nordic\nrf54l_05_10_15.dtsi:737 */
			regulators: regulator@120000 {
				compatible = "nordic,nrf54l-regulators"; /* in zephyr\dts\vendor\nordic\nrf54l_05_10_15.dtsi:738 */
				reg = < 0x120000 0x1000 >;               /* in zephyr\dts\vendor\nordic\nrf54l_05_10_15.dtsi:739 */
				status = "disabled";                     /* in zephyr\dts\vendor\nordic\nrf54l_05_10_15.dtsi:740 */
				#address-cells = < 0x1 >;                /* in zephyr\dts\vendor\nordic\nrf54l_05_10_15.dtsi:741 */
				#size-cells = < 0x1 >;                   /* in zephyr\dts\vendor\nordic\nrf54l_05_10_15.dtsi:742 */

				/* node '/soc/peripheral@50000000/regulator@120000/regulator@120600' defined in zephyr\dts\vendor\nordic\nrf54l_05_10_15.dtsi:744 */
				vregmain: regulator@120600 {
					compatible = "nordic,nrf5x-regulator"; /* in zephyr\dts\vendor\nordic\nrf54l_05_10_15.dtsi:745 */
					reg = < 0x120600 0x1 >;                /* in zephyr\dts\vendor\nordic\nrf54l_05_10_15.dtsi:746 */
					status = "disabled";                   /* in zephyr\dts\vendor\nordic\nrf54l_05_10_15.dtsi:747 */
					regulator-name = "VREGMAIN";           /* in zephyr\dts\vendor\nordic\nrf54l_05_10_15.dtsi:748 */
					regulator-initial-mode = < 0x0 >;      /* in zephyr\dts\vendor\nordic\nrf54l_05_10_15.dtsi:749 */
				};
			};
		};

		/* node '/soc/rram-controller@5004b000' defined in zephyr\dts\vendor\nordic\nrf54l_05_10_15.dtsi:754 */
		rram_controller: rram-controller@5004b000 {
			compatible = "nordic,rram-controller"; /* in zephyr\dts\vendor\nordic\nrf54l_05_10_15.dtsi:755 */
			reg = < 0x5004b000 0x1000 >;           /* in zephyr\dts\vendor\nordic\nrf54l_05_10_15.dtsi:756 */
			ranges;                                /* in zephyr\dts\vendor\nordic\nrf54l_05_10_15.dtsi:757 */
			#address-cells = < 0x1 >;              /* in zephyr\dts\vendor\nordic\nrf54l_05_10_15.dtsi:758 */
			#size-cells = < 0x1 >;                 /* in zephyr\dts\vendor\nordic\nrf54l_05_10_15.dtsi:759 */
			interrupts = < 0x4b 0x1 >;             /* in zephyr\dts\vendor\nordic\nrf54l_05_10_15.dtsi:760 */

			/* node '/soc/rram-controller@5004b000/rram@0' defined in zephyr\dts\vendor\nordic\nrf54l_05_10_15.dtsi:762 */
			cpuapp_rram: rram@0 {
				compatible = "soc-nv-flash";   /* in zephyr\dts\vendor\nordic\nrf54l_05_10_15.dtsi:763 */
				erase-block-size = < 0x1000 >; /* in zephyr\dts\vendor\nordic\nrf54l_05_10_15.dtsi:764 */
				write-block-size = < 0x10 >;   /* in zephyr\dts\vendor\nordic\nrf54l_05_10_15.dtsi:765 */
				status = "okay";               /* in zephyr\dts\vendor\nordic\nrf54l_05_10_15.dtsi:766 */
				#address-cells = < 0x1 >;      /* in zephyr\dts\vendor\nordic\nrf54l_05_10_15.dtsi:767 */
				#size-cells = < 0x1 >;         /* in zephyr\dts\vendor\nordic\nrf54l_05_10_15.dtsi:768 */
				reg = < 0x0 0x17d000 >;        /* in zephyr\dts\vendor\nordic\nrf54l15.dtsi:15 */
				ranges = < 0x0 0x0 0x17d000 >; /* in zephyr\dts\vendor\nordic\nrf54l15.dtsi:16 */

				/* node '/soc/rram-controller@5004b000/rram@0/partitions' defined in ..\..\Users\salamid1\AppData\Local\Temp\senswear_fig4a_1164e335\boards\SenseraTechnologies\SensWear\SensWear_nrf54l15_cpuapp.dts:64 */
				partitions {
					compatible = "fixed-partitions"; /* in ..\..\Users\salamid1\AppData\Local\Temp\senswear_fig4a_1164e335\boards\SenseraTechnologies\SensWear\SensWear_nrf54l15_cpuapp.dts:65 */
					#address-cells = < 0x1 >;        /* in ..\..\Users\salamid1\AppData\Local\Temp\senswear_fig4a_1164e335\boards\SenseraTechnologies\SensWear\SensWear_nrf54l15_cpuapp.dts:66 */
					#size-cells = < 0x1 >;           /* in ..\..\Users\salamid1\AppData\Local\Temp\senswear_fig4a_1164e335\boards\SenseraTechnologies\SensWear\SensWear_nrf54l15_cpuapp.dts:67 */

					/* node '/soc/rram-controller@5004b000/rram@0/partitions/partition@0' defined in ..\..\Users\salamid1\AppData\Local\Temp\senswear_fig4a_1164e335\boards\SenseraTechnologies\SensWear\SensWear_nrf54l15_cpuapp.dts:69 */
					slot0_partition: partition@0 {
						label = "image-0";      /* in ..\..\Users\salamid1\AppData\Local\Temp\senswear_fig4a_1164e335\boards\SenseraTechnologies\SensWear\SensWear_nrf54l15_cpuapp.dts:70 */
						reg = < 0x0 0x15c000 >; /* in ..\..\Users\salamid1\AppData\Local\Temp\senswear_fig4a_1164e335\boards\SenseraTechnologies\SensWear\SensWear_nrf54l15_cpuapp.dts:71 */
					};

					/* node '/soc/rram-controller@5004b000/rram@0/partitions/partition@15c000' defined in ..\..\Users\salamid1\AppData\Local\Temp\senswear_fig4a_1164e335\boards\SenseraTechnologies\SensWear\SensWear_nrf54l15_cpuapp.dts:74 */
					storage_partition: partition@15c000 {
						label = "storage";         /* in ..\..\Users\salamid1\AppData\Local\Temp\senswear_fig4a_1164e335\boards\SenseraTechnologies\SensWear\SensWear_nrf54l15_cpuapp.dts:75 */
						reg = < 0x15c000 0x9000 >; /* in ..\..\Users\salamid1\AppData\Local\Temp\senswear_fig4a_1164e335\boards\SenseraTechnologies\SensWear\SensWear_nrf54l15_cpuapp.dts:76 */
					};
				};
			};
		};

		/* node '/soc/memory@50041000' defined in zephyr\dts\vendor\nordic\nrf54l_05_10_15.dtsi:772 */
		nrf_mpc: memory@50041000 {
			compatible = "nordic,nrf-mpc";     /* in zephyr\dts\vendor\nordic\nrf54l_05_10_15.dtsi:773 */
			reg = < 0x50041000 0x1000 >;       /* in zephyr\dts\vendor\nordic\nrf54l_05_10_15.dtsi:774 */
			#address-cells = < 0x1 >;          /* in zephyr\dts\vendor\nordic\nrf54l_05_10_15.dtsi:775 */
			#size-cells = < 0x1 >;             /* in zephyr\dts\vendor\nordic\nrf54l_05_10_15.dtsi:776 */
			override-num = < 0x5 >;            /* in zephyr\dts\vendor\nordic\nrf54l_05_10_15.dtsi:777 */
			override-granularity = < 0x1000 >; /* in zephyr\dts\vendor\nordic\nrf54l_05_10_15.dtsi:778 */
		};

		/* node '/soc/cpuapp-ppb-bus' defined in zephyr\dts\vendor\nordic\nrf54l_05_10_15.dtsi:781 */
		cpuapp_ppb: cpuapp-ppb-bus {
			#address-cells = < 0x1 >;  /* in zephyr\dts\vendor\nordic\nrf54l_05_10_15.dtsi:782 */
			#size-cells = < 0x1 >;     /* in zephyr\dts\vendor\nordic\nrf54l_05_10_15.dtsi:783 */
			compatible = "simple-bus"; /* in zephyr\dts\arm\nordic\nrf54l_05_10_15_cpuapp.dtsi:65 */
			ranges;                    /* in zephyr\dts\arm\nordic\nrf54l_05_10_15_cpuapp.dtsi:66 */

			/* node '/soc/cpuapp-ppb-bus/interrupt-controller@e000e100' defined in zephyr\dts\vendor\nordic\nrf54l_05_10_15.dtsi:785 */
			cpuapp_nvic: nvic: interrupt-controller@e000e100 {
				#address-cells = < 0x1 >;            /* in zephyr\dts\vendor\nordic\nrf54l_05_10_15.dtsi:786 */
				compatible = "arm,v8m-nvic";         /* in zephyr\dts\vendor\nordic\nrf54l_05_10_15.dtsi:787 */
				reg = < 0xe000e100 0xc00 >;          /* in zephyr\dts\vendor\nordic\nrf54l_05_10_15.dtsi:788 */
				arm,num-irq-priority-bits = < 0x3 >; /* in zephyr\dts\vendor\nordic\nrf54l_05_10_15.dtsi:789 */
				interrupt-controller;                /* in zephyr\dts\vendor\nordic\nrf54l_05_10_15.dtsi:790 */
				#interrupt-cells = < 0x2 >;          /* in zephyr\dts\vendor\nordic\nrf54l_05_10_15.dtsi:791 */
				phandle = < 0x2 >;                   /* in zephyr\dts\arm\nordic\nrf54l_05_10_15_cpuapp.dtsi:24 */
			};

			/* node '/soc/cpuapp-ppb-bus/timer@e000e010' defined in zephyr\dts\vendor\nordic\nrf54l_05_10_15.dtsi:794 */
			cpuapp_systick: systick: timer@e000e010 {
				compatible = "arm,armv8m-systick"; /* in zephyr\dts\vendor\nordic\nrf54l_05_10_15.dtsi:795 */
				reg = < 0xe000e010 0x10 >;         /* in zephyr\dts\vendor\nordic\nrf54l_05_10_15.dtsi:796 */
				status = "disabled";               /* in zephyr\dts\vendor\nordic\nrf54l_05_10_15.dtsi:797 */
			};
		};
	};

	/* node '/chosen' defined in zephyr\dts\arm\nordic\nrf54l_05_10_15_cpuapp.dtsi:17 */
	chosen {
		zephyr,bt-hci = &bt_hci_sdc;                /* in zephyr\dts\arm\nordic\nrf54l_05_10_15_cpuapp.dtsi:18 */
		zephyr,entropy = &psa_rng;                  /* in zephyr\dts\arm\nordic\nrf54l_05_10_15_cpuapp.dtsi:19 */
		zephyr,console = &uart30;                   /* in ..\..\Users\salamid1\AppData\Local\Temp\senswear_fig4a_1164e335\boards\SenseraTechnologies\SensWear\SensWear_nrf54l15_cpuapp.dts:17 */
		zephyr,shell-uart = &uart30;                /* in ..\..\Users\salamid1\AppData\Local\Temp\senswear_fig4a_1164e335\boards\SenseraTechnologies\SensWear\SensWear_nrf54l15_cpuapp.dts:18 */
		zephyr,code-partition = &slot0_partition;   /* in ..\..\Users\salamid1\AppData\Local\Temp\senswear_fig4a_1164e335\boards\SenseraTechnologies\SensWear\SensWear_nrf54l15_cpuapp.dts:19 */
		zephyr,sram = &cpuapp_sram;                 /* in ..\..\Users\salamid1\AppData\Local\Temp\senswear_fig4a_1164e335\boards\SenseraTechnologies\SensWear\SensWear_nrf54l15_cpuapp.dts:20 */
		zephyr,flash = &cpuapp_rram;                /* in ..\..\Users\salamid1\AppData\Local\Temp\senswear_fig4a_1164e335\boards\SenseraTechnologies\SensWear\SensWear_nrf54l15_cpuapp.dts:21 */
		zephyr,flash-controller = &rram_controller; /* in ..\..\Users\salamid1\AppData\Local\Temp\senswear_fig4a_1164e335\boards\SenseraTechnologies\SensWear\SensWear_nrf54l15_cpuapp.dts:22 */
	};

	/* node '/rng' defined in zephyr\dts\arm\nordic\nrf54l_05_10_15_cpuapp.dtsi:28 */
	rng: rng {
		status = "disabled";                      /* in zephyr\dts\arm\nordic\nrf54l_05_10_15_cpuapp.dtsi:29 */
		compatible = "nordic,nrf-cracen-ctrdrbg"; /* in zephyr\dts\arm\nordic\nrf54l_05_10_15_cpuapp.dtsi:30 */
	};

	/* node '/psa-rng' defined in zephyr\dts\arm\nordic\nrf54l_05_10_15_cpuapp.dtsi:33 */
	psa_rng: psa-rng {
		compatible = "zephyr,psa-crypto-rng"; /* in zephyr\dts\arm\nordic\nrf54l_05_10_15_cpuapp.dtsi:34 */
		status = "okay";                      /* in zephyr\dts\arm\nordic\nrf54l_05_10_15_cpuapp.dtsi:35 */
	};

	/* node '/sys_i2c' defined in ..\..\Users\salamid1\AppData\Local\Temp\senswear_fig4a_1164e335\boards\SenseraTechnologies\SensWear\SensWear_nrf54l15_cpuapp.dts:30 */
	sys_i2c: sys_i2c {
		compatible = "senswear,sys-i2c"; /* in ..\..\Users\salamid1\AppData\Local\Temp\senswear_fig4a_1164e335\boards\SenseraTechnologies\SensWear\SensWear_nrf54l15_cpuapp.dts:31 */
		controller = < &i2c21 >;         /* in ..\..\Users\salamid1\AppData\Local\Temp\senswear_fig4a_1164e335\boards\SenseraTechnologies\SensWear\SensWear_nrf54l15_cpuapp.dts:32 */
		status = "okay";                 /* in ..\..\Users\salamid1\AppData\Local\Temp\senswear_fig4a_1164e335\boards\SenseraTechnologies\SensWear\SensWear_nrf54l15_cpuapp.dts:33 */
	};

	/* node '/sys_spi' defined in ..\..\Users\salamid1\AppData\Local\Temp\senswear_fig4a_1164e335\boards\SenseraTechnologies\SensWear\SensWear_nrf54l15_cpuapp.dts:36 */
	sys_spi: sys_spi {
		compatible = "senswear,sys-spi"; /* in ..\..\Users\salamid1\AppData\Local\Temp\senswear_fig4a_1164e335\boards\SenseraTechnologies\SensWear\SensWear_nrf54l15_cpuapp.dts:37 */
		controller = < &spi00 >;         /* in ..\..\Users\salamid1\AppData\Local\Temp\senswear_fig4a_1164e335\boards\SenseraTechnologies\SensWear\SensWear_nrf54l15_cpuapp.dts:38 */
		status = "okay";                 /* in ..\..\Users\salamid1\AppData\Local\Temp\senswear_fig4a_1164e335\boards\SenseraTechnologies\SensWear\SensWear_nrf54l15_cpuapp.dts:39 */
	};

	/* node '/rtc' defined in ..\..\Users\salamid1\AppData\Local\Temp\senswear_fig4a_1164e335\boards\SenseraTechnologies\SensWear\SensWear_nrf54l15_cpuapp.dts:48 */
	rtc0: rtc {
		compatible = "senswear,rtc"; /* in ..\..\Users\salamid1\AppData\Local\Temp\senswear_fig4a_1164e335\boards\SenseraTechnologies\SensWear\SensWear_nrf54l15_cpuapp.dts:49 */
		status = "okay";             /* in ..\..\Users\salamid1\AppData\Local\Temp\senswear_fig4a_1164e335\boards\SenseraTechnologies\SensWear\SensWear_nrf54l15_cpuapp.dts:50 */
	};

	/* node '/daughter-board' defined in ..\..\Users\salamid1\AppData\Local\Temp\senswear_fig4a_1164e335\boards\SenseraTechnologies\SensWear\SensWear_nrf54l15_cpuapp.dts:179 */
	daughter_board_if: daughter-board {
		compatible = "senswear,daughter-connector";    /* in ..\..\Users\salamid1\AppData\Local\Temp\senswear_fig4a_1164e335\boards\SenseraTechnologies\SensWear\SensWear_nrf54l15_cpuapp.dts:180 */
		#gpio-cells = < 0x2 >;                         /* in ..\..\Users\salamid1\AppData\Local\Temp\senswear_fig4a_1164e335\boards\SenseraTechnologies\SensWear\SensWear_nrf54l15_cpuapp.dts:181 */
		gpio-map-mask = < 0xffffffff 0xffffffc0 >;     /* in ..\..\Users\salamid1\AppData\Local\Temp\senswear_fig4a_1164e335\boards\SenseraTechnologies\SensWear\SensWear_nrf54l15_cpuapp.dts:182 */
		gpio-map-pass-thru = < 0x0 0x3f >;             /* in ..\..\Users\salamid1\AppData\Local\Temp\senswear_fig4a_1164e335\boards\SenseraTechnologies\SensWear\SensWear_nrf54l15_cpuapp.dts:183 */
		gpio-map = < 0x0 0x0 &gpio1 0xe 0x0 >,
		           < 0x1 0x0 &gpio1 0xd 0x0 >,
		           < 0x2 0x0 &gpio1 0xc 0x0 >,
		           < 0x3 0x0 &gpio1 0xb 0x0 >;         /* in ..\..\Users\salamid1\AppData\Local\Temp\senswear_fig4a_1164e335\boards\SenseraTechnologies\SensWear\SensWear_nrf54l15_cpuapp.dts:184 */
		gpio-line-names = "SENSOR_GPIO_0",
		                  "SENSOR_GPIO_1",
		                  "SENSOR_GPIO_2",
		                  "SENSOR_GPIO_3";             /* in ..\..\Users\salamid1\AppData\Local\Temp\senswear_fig4a_1164e335\boards\SenseraTechnologies\SensWear\SensWear_nrf54l15_cpuapp.dts:188 */
		sensor-gpios = < &daughter_board_if 0x0 0x0 >,
		               < &daughter_board_if 0x1 0x0 >,
		               < &daughter_board_if 0x2 0x0 >,
		               < &daughter_board_if 0x3 0x0 >; /* in ..\..\Users\salamid1\AppData\Local\Temp\senswear_fig4a_1164e335\boards\SenseraTechnologies\SensWear\SensWear_nrf54l15_cpuapp.dts:195 */
		status = "okay";                               /* in ..\..\Users\salamid1\AppData\Local\Temp\senswear_fig4a_1164e335\boards\SenseraTechnologies\SensWear\SensWear_nrf54l15_cpuapp.dts:199 */
		phandle = < 0x12 >;                            /* in ..\..\Users\salamid1\AppData\Local\Temp\senswear_fig4a_1164e335\boards\SenseraTechnologies\SensWear\SensWear_nrf54l15_cpuapp.dts:195 */
	};
};
